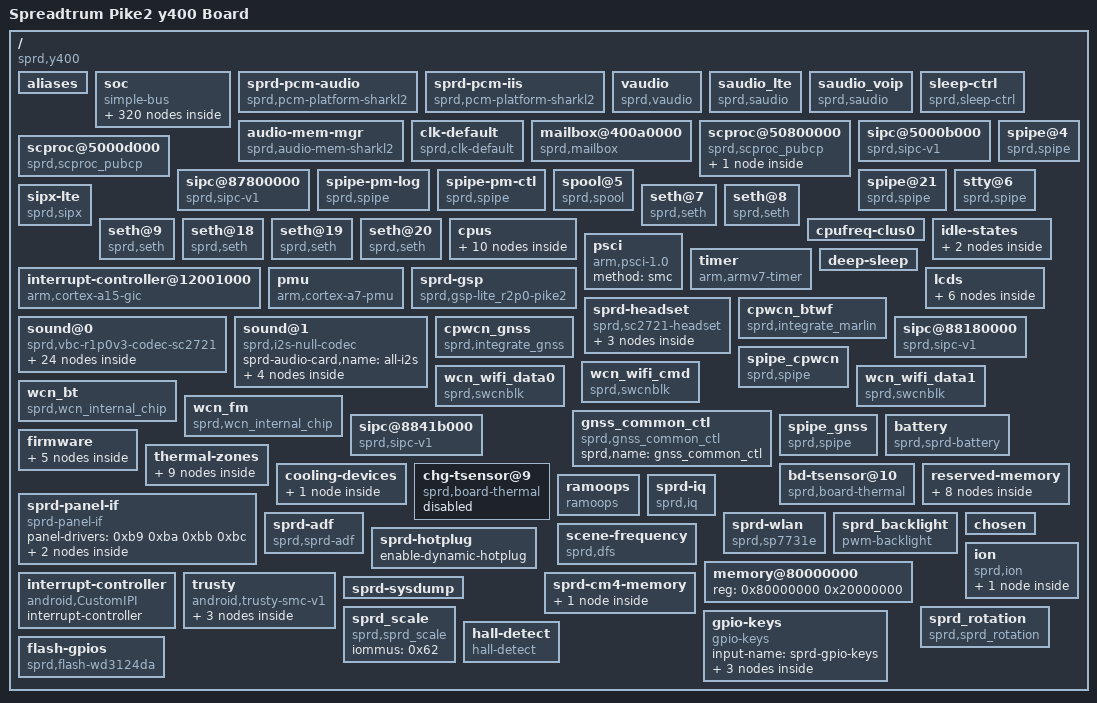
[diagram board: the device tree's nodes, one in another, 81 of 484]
/dts-v1/;

/ {
	interrupt-parent = <0x1>;
	#address-cells = <0x1>;
	#size-cells = <0x1>;
	cpuinfo_hardware = "Spreadtrum SC7731e";
	model = "Spreadtrum Pike2 y400 Board";
	compatible = "sprd,y400", "sprd,sc7731e";
	sprd,sc-id = <0x1e33 0x1 0x20000>;

	aliases {
		serial0 = "/soc/ap-apb/serial@70000000";
		serial1 = "/soc/ap-apb/serial@70100000";
		i2c0 = "/soc/ap-apb/i2c@70500000";
		i2c1 = "/soc/ap-apb/i2c@70600000";
		i2c2 = "/soc/ap-apb/i2c@70700000";
		spi0 = "/soc/ap-apb/spi@70a00000";
		spi1 = "/soc/ap-apb/spi@70b00000";
		hwspinlock1 = "/soc/aon/hwspinlock@40060000";
		thm-sensor0 = "/soc/aon/cpu-thm@402f0000";
		cooling-device0 = "/cooling-devices/cluster0-cooling";
		thm-sensor9 = "/chg-tsensor@9";
		thm-sensor10 = "/bd-tsensor@10";
		thm-sensor11 = "/thermal-zones/cpu-thmzone";
	};

	soc {
		compatible = "simple-bus";
		#address-cells = <0x1>;
		#size-cells = <0x1>;
		ranges;

		syscon@20e00000 {
			compatible = "sprd,sys-ap-ahb", "syscon";
			reg = <0x20e00000 0x100000>;
			hwlocks = <0x2 0x1>;
			hwlock-names = "syscon";
			linux,phandle = <0x2e>;
			phandle = <0x2e>;
		};

		syscon@33100000 {
			compatible = "sprd,anlg_wrap_wcn", "syscon";
			reg = <0x33100000 0x10000>;
			hwlocks = <0x2 0x1>;
			hwlock-names = "syscon";
			linux,phandle = <0xad>;
			phandle = <0xad>;
		};

		syscon@402b0000 {
			compatible = "sprd,sys-pmu-apb", "syscon";
			reg = <0x402b0000 0x10000>;
			hwlocks = <0x2 0x1>;
			hwlock-names = "syscon";
			linux,phandle = <0x4d>;
			phandle = <0x4d>;
		};

		syscon@402e0000 {
			compatible = "sprd,sys-aon-apb", "syscon";
			reg = <0x402e0000 0x10000>;
			hwlocks = <0x2 0x1>;
			hwlock-names = "syscon";
			linux,phandle = <0x16>;
			phandle = <0x16>;
		};

		syscon@40350000 {
			compatible = "sprd,anlg_phy_g1", "syscon";
			reg = <0x40350000 0x3000>;
			hwlocks = <0x2 0x1>;
			hwlock-names = "syscon";
		};

		syscon@40353000 {
			compatible = "sprd,anlg_phy_g2", "syscon";
			reg = <0x40353000 0x3000>;
			hwlocks = <0x2 0x1>;
			hwlock-names = "syscon";
		};

		syscon@40356000 {
			compatible = "sprd,anlg_phy_g3", "syscon";
			reg = <0x40356000 0x3000>;
			hwlocks = <0x2 0x1>;
			hwlock-names = "syscon";
		};

		syscon@40359000 {
			compatible = "sprd,anlg_phy_g5", "syscon";
			reg = <0x40359000 0x3000>;
			hwlocks = <0x2 0x1>;
			hwlock-names = "syscon";
		};

		syscon@60100000 {
			compatible = "sprd,sys-gpu-ahb", "syscon";
			reg = <0x60100000 0x100000>;
			hwlocks = <0x2 0x1>;
			hwlock-names = "syscon";
			linux,phandle = <0x5b>;
			phandle = <0x5b>;
		};

		syscon@60d00000 {
			compatible = "sprd,sys-mm-ahb", "syscon";
			reg = <0x60d00000 0x100000>;
			hwlocks = <0x2 0x1>;
			hwlock-names = "syscon";
			linux,phandle = <0x60>;
			phandle = <0x60>;
		};

		syscon@71300000 {
			compatible = "sprd,sys-ap-apb", "syscon";
			reg = <0x71300000 0x100000>;
			hwlocks = <0x2 0x1>;
			hwlock-names = "syscon";
			linux,phandle = <0x2d>;
			phandle = <0x2d>;
		};

		funnel-soc@10001000 {
			compatible = "arm,coresight-funnel", "arm,primecell";
			reg = <0x10001000 0x1000>;
			clocks = <0x3>;
			clock-names = "apb_pclk";

			ports {
				#address-cells = <0x1>;
				#size-cells = <0x0>;

				port@0 {
					reg = <0x0>;

					endpoint {
						remote-endpoint = <0x4>;
						linux,phandle = <0x6>;
						phandle = <0x6>;
					};
				};

				port@1 {
					reg = <0x0>;

					endpoint {
						slave-mode;
						remote-endpoint = <0x5>;
						linux,phandle = <0x7>;
						phandle = <0x7>;
					};
				};
			};
		};

		tmc-etb@10003000 {
			compatible = "arm,coresight-tmc", "arm,primecell";
			reg = <0x10003000 0x1000>;
			clocks = <0x3>;
			clock-names = "apb_pclk";

			port {

				endpoint {
					slave-mode;
					remote-endpoint = <0x6>;
					linux,phandle = <0x4>;
					phandle = <0x4>;
				};
			};
		};

		cs-ts@10009000 {
			compatible = "arm,coresight-ts", "arm,primecell";
			reg = <0x10009000 0x1000>;
		};

		funnel-core@10220000 {
			compatible = "arm,coresight-funnel", "arm,primecell";
			reg = <0x10220000 0x1000>;
			clocks = <0x3>;
			clock-names = "apb_pclk";

			ports {
				#address-cells = <0x1>;
				#size-cells = <0x0>;

				port@0 {
					reg = <0x0>;

					endpoint {
						remote-endpoint = <0x7>;
						linux,phandle = <0x5>;
						phandle = <0x5>;
					};
				};

				port@1 {
					reg = <0x0>;

					endpoint {
						slave-mode;
						remote-endpoint = <0x8>;
						linux,phandle = <0xf>;
						phandle = <0xf>;
					};
				};

				port@2 {
					reg = <0x1>;

					endpoint {
						slave-mode;
						remote-endpoint = <0x9>;
						linux,phandle = <0x11>;
						phandle = <0x11>;
					};
				};

				port@3 {
					reg = <0x2>;

					endpoint {
						slave-mode;
						remote-endpoint = <0xa>;
						linux,phandle = <0x13>;
						phandle = <0x13>;
					};
				};

				port@4 {
					reg = <0x3>;

					endpoint {
						slave-mode;
						remote-endpoint = <0xb>;
						linux,phandle = <0x15>;
						phandle = <0x15>;
					};
				};
			};
		};

		etm-core0@1025c000 {
			compatible = "arm,coresight-etm3x", "arm,primecell";
			reg = <0x1025c000 0x1000>;
			cpu = <0xc>;
			clocks = <0x3 0xd 0xe>;
			clock-names = "apb_pclk", "clk_cs", "cs_src";

			port {

				endpoint {
					remote-endpoint = <0xf>;
					linux,phandle = <0x8>;
					phandle = <0x8>;
				};
			};
		};

		etm-core1@1025d000 {
			compatible = "arm,coresight-etm3x", "arm,primecell";
			reg = <0x1025d000 0x1000>;
			cpu = <0x10>;
			clocks = <0x3 0xd 0xe>;
			clock-names = "apb_pclk", "clk_cs", "cs_src";

			port {

				endpoint {
					remote-endpoint = <0x11>;
					linux,phandle = <0x9>;
					phandle = <0x9>;
				};
			};
		};

		etm-core2@1025e000 {
			compatible = "arm,coresight-etm3x", "arm,primecell";
			reg = <0x1025e000 0x1000>;
			cpu = <0x12>;
			clocks = <0x3 0xd 0xe>;
			clock-names = "apb_pclk", "clk_cs", "cs_src";

			port {

				endpoint {
					remote-endpoint = <0x13>;
					linux,phandle = <0xa>;
					phandle = <0xa>;
				};
			};
		};

		etm-core3@1025f000 {
			compatible = "arm,coresight-etm3x", "arm,primecell";
			reg = <0x1025f000 0x1000>;
			cpu = <0x14>;
			clocks = <0x3 0xd 0xe>;
			clock-names = "apb_pclk", "clk_cs", "cs_src";

			port {

				endpoint {
					remote-endpoint = <0x15>;
					linux,phandle = <0xb>;
					phandle = <0xb>;
				};
			};
		};

		pub {
			compatible = "simple-bus";
			#address-cells = <0x1>;
			#size-cells = <0x1>;
			ranges;

			syscon@30000000 {
				compatible = "sprd,sys-dmc-phy", "syscon";
				reg = <0x30000000 0x400>;
				sprd,sizel_off = <0x1b4>;
				sprd,sizeh_off = <0x1b8>;
			};

			bm-perf@30040000 {
				compatible = "sprd,bm-perf-pike2";
				reg = <0x30040000 0x80000 0x0 0x0 0x40270000 0x10000 0x300e0000 0x4 0x0 0x0>;
				interrupts = <0x0 0x56 0x4>;
				reg-names = "pub0", "pub1", "timer", "pub0_glb", "pub1_glb";
				sprd,syscon-aon-glb = <0x16>;
				sprd,bm-dma = <0xb>;
				dma-names = "bm_chn";
				dmas = <0x17 0x9>;
			};

			dmc-mpu@300e0000 {
				compatible = "sprd,dmc-mpu-r3p0";
				reg = <0x300e0000 0x10000>;
				interrupts = <0x0 0x3d 0x4>;
				sprd,channel-num = <0x8>;
				sprd,channel-names = "WCN/AON", "GPU", "DISP/ISP", "CA7", "CP", "VSP", "AP", "SHARED";
				sprd,ranges = <0x88000000 0x88380000 0x0 0x0 0x0 0x0 0x0 0x0 0x0 0x0 0x0 0x0 0x0 0x0 0x0 0x0>;
				sprd,chn-config = <0x1 0x0 0x1 0x0 0x1 0x1 0x0 0x1 0x1 0x0 0x1 0x1 0x0 0x1 0x1 0x0 0x1 0x1 0x0 0x1 0x1 0x0 0x1 0x1>;
				sprd,id-config = <0x1 0xc0 0xc0 0x0 0x0 0x0 0x0 0x0 0x0 0x0 0x0 0x0 0x0 0x0 0x0 0x0 0x0 0x0 0x0 0x0 0x0 0x0 0x0 0x0>;
				sprd,shared-chn = "WCN/AON";
				sprd,ddr-offset = <0x80000000>;
				status = "okay";
				sprd,panic;
			};
		};

		ap-apb {
			compatible = "simple-bus";
			#address-cells = <0x1>;
			#size-cells = <0x1>;
			ranges;

			serial@70000000 {
				compatible = "sprd,sc9836-uart";
				reg = <0x70000000 0x100>;
				interrupts = <0x0 0x2 0x4>;
				clock-names = "uart", "source", "enable";
				status = "okay";
				clocks = <0x18 0x3 0x19 0xd>;
			};

			serial@70100000 {
				compatible = "sprd,sc9836-uart";
				reg = <0x70100000 0x100>;
				interrupts = <0x0 0x3 0x4>;
				clock-names = "uart", "source", "enable";
				status = "okay";
				clocks = <0x1a 0x3 0x19 0xe>;
			};

			i2c@70500000 {
				compatible = "sprd,r8p0-i2c";
				reg = <0x70500000 0x1000>;
				interrupts = <0x0 0xb 0x4>;
				clock-names = "i2c", "source", "enable";
				clock-frequency = <0x61a80>;
				#address-cells = <0x1>;
				#size-cells = <0x0>;
				status = "okay";
				clocks = <0x1b 0x3 0x19 0x8>;

				sensor-main@3c {
					compatible = "sprd,sensor-main";
					reg = <0x3c>;
					clock-names = "clk_src", "sensor_eb", "clk_96m", "clk_76m8", "clk_48m", "clk_26m";
					clocks = <0x1c 0x1d 0x1 0x1e 0x1f 0x20 0x3>;
					vddio-supply = <0x21>;
					vddcama-supply = <0x22>;
					vddcamd-supply = <0x23>;
					vddcammot-supply = <0x24>;
					reset-gpios = <0x25 0x25 0x0>;
					power-down-gpios = <0x25 0x26 0x0>;
					host = "dcam0";
					linux,phandle = <0x58>;
					phandle = <0x58>;

					port {

						endpoint {
							remote-endpoint = <0x26>;
						};
					};
				};

				sensor-sub@21 {
					compatible = "sprd,sensor-sub";
					reg = <0x21>;
					clock-names = "clk_src", "sensor_eb", "clk_96m", "clk_76m8", "clk_48m", "clk_26m";
					clocks = <0x1c 0x1d 0x1 0x1e 0x1f 0x20 0x3>;
					vddio-supply = <0x21>;
					vddcama-supply = <0x22>;
					vddcamd-supply = <0x23>;
					vddcammot-supply = <0x24>;
					reset-gpios = <0x25 0x2e 0x0>;
					power-down-gpios = <0x25 0x27 0x0>;
					host = "dcam0";
					linux,phandle = <0x59>;
					phandle = <0x59>;

					port {

						endpoint {
							remote-endpoint = <0x26>;
						};
					};
				};
			};

			i2c@70600000 {
				compatible = "sprd,r8p0-i2c";
				reg = <0x70600000 0x1000>;
				interrupts = <0x0 0xc 0x4>;
				clock-names = "i2c", "source", "enable";
				clock-frequency = <0x61a80>;
				#address-cells = <0x1>;
				#size-cells = <0x0>;
				status = "okay";
				clocks = <0x27 0x3 0x19 0x9>;

				accelerometer@26 {
					compatible = "da,da213";
					reg = <0x26>;
				};

				megnetometer@0c {
					compatible = "vtc,af6133";
					reg = <0xc>;
				};

				elan@49 {
					reg = <0x49>;
					compatible = "epl,epl259x";
					epl,irq-gpio = <0x25 0x38 0x0>;
				};

				kionix_acc@0e {
					compatible = "Kionix,accel";
					reg = <0xe>;
					poll_interval = <0xa>;
					min_interval = <0xa>;
					g_range = <0x0>;
					accel_res = <0x3>;
					accel_irq_use_drdy = <0x0>;
					accel_direction = <0x2>;
					gpios = <0x25 0x36 0x0>;
				};
			};

			i2c@70700000 {
				compatible = "sprd,r8p0-i2c";
				reg = <0x70700000 0x1000>;
				interrupts = <0x0 0xd 0x4>;
				clock-names = "i2c", "source", "enable";
				clock-frequency = <0x30d40>;
				#address-cells = <0x1>;
				#size-cells = <0x0>;
				status = "okay";
				clocks = <0x28 0x3 0x19 0xa>;

				ilitek2238_ts@26 {
					status = "okay";
					compatible = "ilitek,2238";
					reg = <0x26>;
					gpios = <0x25 0x3f 0x0 0x25 0x40 0x0>;
					touch,reset-gpio = <0x25 0x3f 0x0>;
					touch,irq-gpio = <0x25 0x40 0x0>;
					vdd_name = "vdd18";
					virtualkeys = <0x190 0x384 0x1e 0x1e 0x50 0x384 0x1e 0x1e 0xf0 0x384 0x1e 0x1e>;
					TP_MAX_X = <0x1e0>;
					TP_MAX_Y = <0x3c0>;
				};

				focaltech@38 {
					compatible = "focaltech,fts";
					reg = <0x38>;
					focaltech,reset-gpio = <0x25 0x3f 0x0>;
					focaltech,irq-gpio = <0x25 0x40 0x0>;
					focaltech,max-touch-number = <0x2>;
					focaltech,display-coords = <0x0 0x0 0x1e0 0x3c0>;
					#focaltech,have-key;
					#focaltech,key-number = <0x3>;
					#focaltech,keys = <0x9e 0xac 0x244>;
					#focaltech,key-y-coord = <0x384>;
					#focaltech,key-x-coords = <0x50 0xf0 0x190>;
				};

				bl_ts@2d {
					compatible = "btl,btl_ts";
					reg = <0x2d>;
					btl,reset-gpio = <0x25 0x3f 0x0>;
					btl,irq-gpio = <0x25 0x40 0x0>;
					vdd_name = "vdd28";
					betterlife,have_virtualkey;
					betterlife,virtualkeys = <0x50 0x384 0x3c 0x2d 0xf0 0x384 0x3c 0x2d 0x190 0x384 0x3c 0x2d>;
					TP_MAX_X = <0x1e0>;
					TP_MAX_Y = <0x3c0>;
				};
			};

			spi@70a00000 {
				compatible = "sprd,spi-r4p0";
				reg = <0x70a00000 0x1000>;
				interrupts = <0x0 0x7 0x4>;
				clock-names = "spi", "source", "enable";
				sprd,dma-mode = <0x0>;
				sprd,rxtx-dma = <0xb 0xc>;
				dma-names = "rx_chn", "tx_chn";
				dmas = <0x29 0xb 0x29 0xc>;
				#address-cells = <0x1>;
				#size-cells = <0x0>;
				status = "disabled";
				clocks = <0x2a 0x3 0x19 0x5>;
			};

			spi@70b00000 {
				compatible = "sprd,spi-r4p0";
				reg = <0x70b00000 0x1000>;
				interrupts = <0x0 0x8 0x4>;
				clock-names = "spi", "source", "enable";
				sprd,dma-mode = <0x0>;
				sprd,rxtx-dma = <0xd 0xe>;
				dma-names = "rx_chn", "tx_chn";
				dmas = <0x29 0xd 0x29 0xe>;
				#address-cells = <0x1>;
				#size-cells = <0x0>;
				status = "disabled";
				clocks = <0x2b 0x3 0x2c 0x9>;
			};

			i2s@70d00000 {
				compatible = "sprd,i2s";
				#sound-dai-cells = <0x0>;
				reg = <0x70d00000 0x100000>;
				sprd,dai_name = "i2s_bt_sco0";
				sprd,hw_port = <0x0>;
				sprd,syscon-ap-apb = <0x2d>;
				status = "okay";
				sprd,config_type = "pcm";
				sprd,slave_timeout = <0xf11>;
				sprd,_hw_port = <0x0>;
				sprd,fs = <0x1f40>;
				sprd,bus_type = <0x1>;
				sprd,rtx_mode = <0x3>;
				sprd,byte_per_chan = <0x1>;
				sprd,slave_mode = <0x0>;
				sprd,lsb = <0x0>;
				sprd,lrck = <0x0>;
				sprd,low_for_left = <0x1>;
				sprd,clk_inv = <0x0>;
				sprd,pcm_short_frame = <0x1>;
				sprd,pcm_slot = <0x1>;
				sprd,pcm_cycle = <0x1>;
				sprd,tx_watermark = <0xc>;
				sprd,rx_watermark = <0x14>;
				linux,phandle = <0xac>;
				phandle = <0xac>;
			};

			i2s@70e00000 {
				compatible = "sprd,i2s";
				#sound-dai-cells = <0x0>;
				reg = <0x70e00000 0x100000>;
				sprd,dai_name = "i2s_bt_sco1";
				sprd,hw_port = <0x1>;
				sprd,syscon-ap-apb = <0x2d>;
				status = "disable";
			};

			i2s@70f00000 {
				compatible = "sprd,i2s";
				#sound-dai-cells = <0x0>;
				reg = <0x70f00000 0x100000>;
				sprd,dai_name = "i2s_bt_sco2";
				sprd,hw_port = <0x2>;
				sprd,syscon-ap-apb = <0x2d>;
				status = "disable";
			};

			i2s@71000000 {
				compatible = "sprd,i2s";
				#sound-dai-cells = <0x0>;
				reg = <0x71000000 0x100000>;
				sprd,dai_name = "i2s_bt_sco3";
				sprd,hw_port = <0x3>;
				sprd,syscon-ap-apb = <0x2d>;
				status = "disable";
			};

			syscon@71400000 {
				compatible = "sprd,sys-ap-intc", "syscon";
				reg = <0x71400000 0x10000>;
				linux,phandle = <0x9a>;
				phandle = <0x9a>;
			};

			syscon@71500000 {
				compatible = "sprd,sys-ap-intc", "syscon";
				reg = <0x71500000 0x10000>;
				linux,phandle = <0x9b>;
				phandle = <0x9b>;
			};

			syscon@71600000 {
				compatible = "sprd,sys-ap-intc", "syscon";
				reg = <0x71600000 0x10000>;
				linux,phandle = <0x9c>;
				phandle = <0x9c>;
			};

			syscon@71700000 {
				compatible = "sprd,sys-ap-intc", "syscon";
				reg = <0x71700000 0x10000>;
				linux,phandle = <0x9d>;
				phandle = <0x9d>;
			};
		};

		ap-ahb {
			compatible = "simple-bus";
			#address-cells = <0x1>;
			#size-cells = <0x1>;
			ranges;

			dma-controller@20100000 {
				compatible = "sprd,ap-dma-v2.0";
				reg = <0x20100000 0x4000>;
				interrupts = <0x0 0x32 0x4>;
				#dma-cells = <0x1>;
				#dma-channels = <0x1c>;
				sprd,full-type-offset = <0x0>;
				sprd,syscon-dma-glb = <0x2e>;
				clock-names = "enable";
				clocks = <0x2f 0x5>;
				linux,phandle = <0x29>;
				phandle = <0x29>;
			};

			usb@20200000 {
				compatible = "sprd,usb";
				reg = <0x20200000 0x2000>;
				interrupts = <0x0 0x37 0x4>;
				interrupt-names = "mc";
				clocks = <0x2f 0x4>;
				clock-names = "core_clk";
				phy-type = "usb20_sprd_phy";
				usb-phy = <0x30>;
				phy-names = "usb";
				dr-mode = "peripheral";
				sprd,cable-detection-method = "gpios";
				sprd,vbus-gpios = <0x31 0x0 0x0>;
			};

			sdio@20600000 {
				compatible = "sprd,sdhc-r10";
				reg = <0x20600000 0x1000>;
				interrupts = <0x0 0x3c 0x4>;
				clock-names = "sdio_clk", "sdio_clk_source", "sdio_ahb_enable", "sdio_2x_eb", "sdio_1x_eb";
				clocks = <0x32 0x33 0x2f 0xb 0x2c 0x1 0x2c 0x0>;
				status = "okay";
				sprd,hs400es-dly = <0x45 0x7f 0x30 0x30>;
				sprd,hs400-dly = <0x45 0xaa 0x30 0x30>;
				sprd,hs200-dly = <0x7f 0xaa 0xa8 0xa8>;
				sprd,ddr52-dly = <0x80 0xbe 0x22 0x22>;
				vmmc-supply = <0x34>;
				voltage-ranges = <0xbb8 0xbb8>;
				bus-width = <0x8>;
				non-removable;
				cap-mmc-hw-reset;
				mmc-hs200-1_8v;
				mmc-ddr-1_8v;
				sprd,name = "sdio_emmc";
				no-sdio;
				no-sd;
			};

			sdio@20300000 {
				compatible = "sprd,sdhc-r10";
				reg = <0x20300000 0x1000>;
				interrupts = <0x0 0x39 0x4>;
				clock-names = "sdio_clk", "sdio_clk_source", "sdio_ahb_enable", "sdio_2x_eb", "sdio_1x_eb";
				clocks = <0x35 0x33 0x2f 0x8 0x2c 0x3 0x2c 0x2>;
				status = "okay";
				sprd,sdr104-dly = <0x7f 0xb0 0xb4 0xb4>;
				sprd,sdr50-dly = <0x7f 0x45 0x41 0x41>;
				vmmc-supply = <0x36>;
				vqmmc-supply = <0x37>;
				voltage-ranges = <0xbb8 0xbb8>;
				bus-width = <0x4>;
				sd-uhs-sdr50;
				sprd,name = "sdio_sd";
				no-sdio;
				no-mmc;
			};

			iommu@20800160 {
				compatible = "sprd,iommuexpk2-dispc";
				reg = <0x20800160 0x4 0x20800800 0x60 0x30000000 0x8000000>;
				reg_name = "mmu_interrupt_reg", "mmu_reg", "iova pool";
				status = "okay";
				#iommu-cells = <0x0>;
				linux,phandle = <0x3e>;
				phandle = <0x3e>;
			};

			gsp@20a00000 {
				compatible = "sprd,gsp-core";
				reg = <0x20a00000 0x1000 0x20443000 0x138>;
				core-id = <0x0>;
				kcfg-num = <0x8>;
				interrupts = <0x0 0x33 0x4>;
				iommus = <0x38>;
				sprd,sys-ap-ahb = <0x2e>;
				clock-names = "clk_gsp", "clk_gsp_parent", "clk_gsp_eb";
				clocks = <0x39 0x33 0x2f 0x3>;
				linux,phandle = <0x9e>;
				phandle = <0x9e>;
			};

			iommu@20a00800 {
				compatible = "sprd,iommuexpk2-gsp";
				reg = <0x20a00800 0x4 0x20a00804 0x60 0x10000000 0x10000000>;
				reg_name = "mmu_interrupt_reg", "mmu_reg", "iova pool";
				status = "okay";
				#iommu-cells = <0x0>;
				linux,phandle = <0x38>;
				phandle = <0x38>;
			};

			hsphy@20e00000 {
				compatible = "sprd,pike2-usb-phy";
				reg = <0x20e00000 0x3030>;
				reg-names = "phy_glb_regs";
				sprd,syscon-enable = <0x16>;
				sprd,tune-value = <0x5af33>;
				sprd,vdd-voltage = <0x325aa0>;
				#phy-cells = <0x0>;
				vdd-supply = <0x3a>;
				sprd,efuse-blk-id = <0x29>;
				sprd,efuse-backup = <0x1>;
				linux,phandle = <0x30>;
				phandle = <0x30>;
			};

			dispc@20800000 {
				compatible = "sprd,display-controller";
				reg = <0x20800000 0x1000>;
				dev-id = <0x0>;
				sprd,dpi_clk_div = <0x1>;
				sprd,max_layers = <0x4>;
				sprd,qos = <0x411f0>;
				interrupts = <0x0 0x2e 0x4>;
				clock-src = <0x16e36000 0x927c000>;
				clock-names = "clk_dispc_core_parent", "clk_dispc_dpi_parent", "clk_dispc_core", "clk_dispc_dpi", "clk_dispc_ahb_eb";
				clocks = <0x33 0x3b 0x3c 0x3d 0x2f 0x1>;
				iommus = <0x3e>;
				status = "okay";
				sprd,ip = "dpu-lite-r1p0";
				sprd,soc = "pike2";
				wb-disable = <0x1>;
				linux,phandle = <0xbe>;
				phandle = <0xbe>;

				port {

					endpoint@0 {
						remote-endpoint = <0x3f>;
						linux,phandle = <0x41>;
						phandle = <0x41>;
					};
				};
			};

			dsi@21800000 {
				compatible = "sprd,dsi-controller";
				#address-cells = <0x1>;
				#size-cells = <0x0>;
				dev-id = <0x0>;
				reg = <0x21800000 0x1000>;
				interrupts = <0x0 0x30 0x4 0x0 0x31 0x4>;
				clock-names = "clk_dsi0_ahb_eb";
				clocks = <0x2f 0x0>;
				status = "okay";
				sprd,ip = "sprd,dsi-ctrl-r1p0";
				sprd,soc = "pike2";

				port@0 {
					reg = <0x0>;

					endpoint {
						remote-endpoint = <0x40>;
						linux,phandle = <0x43>;
						phandle = <0x43>;
					};
				};

				port@1 {
					reg = <0x1>;

					endpoint {
						remote-endpoint = <0x41>;
						linux,phandle = <0x3f>;
						phandle = <0x3f>;
					};
				};
			};

			dphy@0 {
				compatible = "sprd,mipi-dsi-phy";
				#address-cells = <0x1>;
				#size-cells = <0x0>;
				reg = <0x21800000 0x1000>;
				status = "okay";
				sprd,ip = "sprd,megacores-sharkle";
				sprd,soc = "pike2";

				port@0 {
					reg = <0x0>;

					endpoint {
						remote-endpoint = <0x42>;
						linux,phandle = <0xbd>;
						phandle = <0xbd>;
					};
				};

				port@1 {
					reg = <0x1>;

					endpoint {
						remote-endpoint = <0x43>;
						linux,phandle = <0x40>;
						phandle = <0x40>;
					};
				};
			};

			lcds {

				lcdffff@0 {
					work-mode = <0x1>;
					bpp = <0x18>;
					lane-number = <0x4>;
					fps = <0x3c>;
					panel-name = "lcd_dummy_mipi_hd";
					power-on-sequence = <0x32 0x1 0x14 0x32 0x0 0x14 0x32 0x1 0x78>;
					power-off-sequence = <0x32 0x0 0x14>;
					init-data = <0x15780002 0x11001500 0x22900>;
					sleep-in = <0x15000002 0x28001578 0x21000>;
					sleep-out = <0x15780002 0x11001500 0x22900>;
					linux,phandle = <0xbc>;
					phandle = <0xbc>;

					display-timings {
						clock-frequency = <0x7a120>;
						hactive = <0x2d0>;
						vactive = <0x500>;
						hback-porch = <0x30>;
						hfront-porch = <0x30>;
						vback-porch = <0x10>;
						vfront-porch = <0x10>;
						hsync-len = <0x8>;
						vsync-len = <0x8>;
					};
				};
			};
		};

		aon {
			compatible = "simple-bus";
			#address-cells = <0x1>;
			#size-cells = <0x1>;
			ranges;

			syscon@0 {
				compatible = "sprd,sys-aon-iram0", "syscon";
				reg = <0x0 0x2000>;
			};

			timer@40050000 {
				compatible = "sprd,bcevt-r4p0";
				reg = <0x40050000 0x14>;
				interrupts = <0x0 0x1c 0x4>;
				clock-frequency = <0x8000>;
			};

			timer@40050020 {
				compatible = "sprd,persistent-clock";
				reg = <0x40050020 0x14>;
				clock-frequency = <0x8000>;
			};

			timer@40050040 {
				compatible = "sprd,gp-timer";
				reg = <0x40050040 0x14>;
				clock-frequency = <0x18cba80>;
				status = "disabled";
			};

			hwspinlock@40060000 {
				compatible = "sprd,hwspinlock-r3p0";
				reg = <0x40060000 0x1000>;
				#hwlock-cells = <0x1>;
				hwlocks-base = <0x0>;
				hwlocks-num = <0x20>;
				clock-names = "enable";
				clocks = <0x44 0x16>;
				linux,phandle = <0x2>;
				phandle = <0x2>;
			};

			dma-controller@40100000 {
				compatible = "sprd,aon-dma-v2.0";
				reg = <0x40100000 0x4000>;
				#dma-cells = <0x1>;
				#dma-channels = <0xd>;
				sprd,full-type-offset = <0x0>;
				sprd,syscon-dma-glb = <0x16>;
				clock-names = "enable";
				clocks = <0x45 0x16>;
				linux,phandle = <0x17>;
				phandle = <0x17>;
			};

			syscon@40200000 {
				compatible = "sprd,sys-aon-intc", "syscon";
				reg = <0x40200000 0x10000>;
				linux,phandle = <0x9f>;
				phandle = <0x9f>;
			};

			gpio-controller@40210000 {
				compatible = "sprd,ap-eic";
				reg = <0x40210000 0x1000 0x40370000 0x1000>;
				gpio-controller;
				#gpio-cells = <0x2>;
				sprd,gpiobase = <0x120>;
				sprd,ngpios = <0x20>;
				interrupt-controller;
				#interrupt-cells = <0x2>;
				interrupts = <0x0 0x25 0x4>;
				linux,phandle = <0xc5>;
				phandle = <0xc5>;
			};

			gpio-controller@402100a0 {
				compatible = "sprd,ap-eic-async";
				reg = <0x402100a0 0x40 0x403700a0 0x40>;
				gpio-controller;
				#gpio-cells = <0x2>;
				sprd,gpiobase = <0x150>;
				sprd,ngpios = <0x20>;
				interrupt-controller;
				#interrupt-cells = <0x2>;
				interrupts = <0x0 0x25 0x4>;
			};

			efuse@40240000 {
				compatible = "sprd,ap_r6p0_efuse";
				sprd,syscon-enable = <0x16>;
				reg = <0x40240000 0x10000>;
				clock-names = "enable";
				clocks = <0x44 0xd>;
				sprd,uid-start = <0x2e 0x1>;
				sprd,uid-end = <0x2f 0x1>;
				sprd,block-start = <0x24>;
				sprd,block-num = <0xc>;
				sprd,block-width = <0x20>;
				hwlocks = <0x2 0x8>;
				hwlock-names = "ap_efuse";
			};

			pwm@40260020 {
				#pwm-cells = <0x2>;
				compatible = "sprd,pwm-r3p0";
				reg = <0x40260020 0x10000>;
				status = "okay";
				clock-names = "sprd_pwm_clk_parent", "clk_pwm";
				clocks = <0x3 0x46>;
				linux,phandle = <0xbf>;
				phandle = <0xbf>;
			};

			gpio-controller@40280000 {
				compatible = "sprd,ap-gpio";
				reg = <0x40280000 0x1000>;
				gpio-controller;
				#gpio-cells = <0x2>;
				sprd,gpiobase = <0x0>;
				sprd,ngpios = <0x100>;
				interrupt-controller;
				#interrupt-cells = <0x2>;
				interrupts = <0x0 0x23 0x4>;
				linux,phandle = <0x25>;
				phandle = <0x25>;
			};

			pinctrl@402a0000 {
				compatible = "sprd,sc9833-pinctrl";
				reg = <0x402a0000 0x10000>;

				reg3-iis0-0 {
					pins = <0x2810643 0x0>;
					linux,phandle = <0x4f>;
					phandle = <0x4f>;
				};

				reg3-iis0-1 {
					pins = <0x2810643 0x1>;
					linux,phandle = <0x51>;
					phandle = <0x51>;
				};

				reg3-iis0-2 {
					pins = <0x2810643 0x2>;
					linux,phandle = <0x50>;
					phandle = <0x50>;
				};

				reg3-iis0-3 {
					pins = <0x2810643 0x3>;
					linux,phandle = <0x52>;
					phandle = <0x52>;
				};

				reg3-iis1-0 {
					pins = <0x2710a33 0x0>;
					linux,phandle = <0x53>;
					phandle = <0x53>;
				};

				reg3-iis1-1 {
					pins = <0x2710a33 0x1>;
					linux,phandle = <0x55>;
					phandle = <0x55>;
				};

				reg3-iis1-2 {
					pins = <0x2710a33 0x2>;
					linux,phandle = <0x54>;
					phandle = <0x54>;
				};

				reg3-iis1-3 {
					pins = <0x2710a33 0x3>;
					linux,phandle = <0x56>;
					phandle = <0x56>;
				};
			};

			avoid-disturb@402e01b0 {
				compatible = "sprd,pike2-ads";
				reg = <0x402e01b0 0x14 0x5000f800 0x800>;
				sprd,ads-off-info = <0x10 0x20 0x20 0x80 0x220 0x800>;
				sprd,sad-dst-id = <0x2 0x3 0x4>;
				sprd,pll-index = <0x1 0x3 0x4>;
				clocks = <0x47 0x48 0x49>;
			};

			cpu-thm@402f0000 {
				compatible = "sprd,r2p0-thm";
				sprd,syscon-enable = <0x16>;
				reg = <0x402f0000 0x10000>;
				clock-names = "enable";
				clocks = <0x45 0x1>;
				#thermal-sensor-cells = <0x1>;
				power-down = <0x0>;
				otp-temp = <0x1d4c0>;
				algor_ver = <0x1>;
				cal_k = <0x387>;
				cal_b = <0x1167a>;
				cal_efuse_blk = <0x2c>;
				cal_efuse_bit = <0xc>;
				ratio_off_bit = <0x5>;
				ratio_sign_bit = <0x4>;
				linux,phandle = <0xb2>;
				phandle = <0xb2>;
			};

			watchdog@40310000 {
				compatible = "sprd,sharkl2-wdt";
				reg = <0x40310000 0x1000>;
				interrupts = <0x0 0x7c 0x4>;
				clock-names = "enable", "rtc_enable";
				sprd,wdt-enable = <0x16>;
				sprd,wdt-phandle = <0x4a>;
				clocks = <0x45 0x8 0x4b 0x9>;
			};

			spi@403c0000 {
				compatible = "sprd,r3p0-adi";
				reg = <0x403c0000 0x10000>;
				#address-cells = <0x1>;
				#size-cells = <0x0>;
				sprd,hw-channels = <0x3 0x8c68 0x21 0x8c20 0x23 0x8cc0 0x24 0x8ccc>;

				pmic@0 {
					compatible = "sprd,sc2720";
					reg = <0x0>;
					spi-max-frequency = <0x18cba80>;
					#address-cells = <0x1>;
					#size-cells = <0x0>;
					interrupt-controller;
					#interrupt-cells = <0x2>;
					interrupts = <0x0 0x26 0x4>;
					sprd,pmic_intc_base = <0xc0>;
					sprd,pmic_intc_irqmax = <0x9>;
					linux,phandle = <0x4c>;
					phandle = <0x4c>;

					timer@00 {
						compatible = "sprd,sc2720-chg-timer";
						reg = <0x0>;
						interrupt-parent = <0x4c>;
						interrupts = <0x6 0x4>;
					};

					watchdog@40 {
						compatible = "sprd,sc2720-wdt";
						reg = <0x40>;
						linux,phandle = <0x4a>;
						phandle = <0x4a>;
					};

					bltc-rgb@180 {
						compatible = "sprd,sc2720-bltc-rgb";
						reg = <0x180>;
						status = "okay";
					};

					flash@1f4 {
						compatible = "sprd,sc2720-flash";
						reg = <0x1f4>;
						status = "okay";
					};

					rtc@200 {
						compatible = "sprd,sc2720-rtc";
						interrupt-parent = <0x4c>;
						interrupts = <0x1 0x4>;
						reg = <0x200>;
					};

					gpio-controller@280 {
						compatible = "sprd,sc2720-eic";
						reg = <0x280>;
						interrupts = <0x4 0x4>;
						interrupt-parent = <0x4c>;
						gpio-controller;
						#gpio-cells = <0x2>;
						sprd,gpiobase = <0x140>;
						sprd,ngpios = <0x10>;
						interrupt-controller;
						#interrupt-cells = <0x2>;
						linux,phandle = <0x31>;
						phandle = <0x31>;
					};

					kpled@1f8 {
						compatible = "sprd,sc2721-kpled";
						brightness_max = <0xff>;
						brightness_min = <0x0>;
						run_mode = <0x1>;
						reg = <0x1f8 0x1fc>;
						status = "disabled";
					};

					efuse@300 {
						compatible = "sprd,sc2720-efuse";
						reg = <0x300>;
						sprd,block-num = <0x20>;
						sprd,block-width = <0x10>;
						hwlocks = <0x2 0xc>;
						hwlock-names = "pmic_efuse";
					};

					typec@380 {
						compatible = "sprd,typec";
						interrupt-parent = <0x4c>;
						interrupts = <0x8 0x4>;
						reg = <0x380>;
						mode = <0x2>;
						tsleep = <0x0>;
						ext-ldo-sw = <0x0>;
						status = "disable";
					};

					adc@400 {
						compatible = "sprd,sc2720-adc";
						reg = <0x400>;
						#io-channel-cells = <0x1>;
						sprd,channel-scale = <0x0 0x0 0x1 0x0 0x2 0x0 0x3 0x0>;
						hwlocks = <0x2 0x4>;
						hwlock-names = "pmic_adc";
						linux,phandle = <0xa5>;
						phandle = <0xa5>;
					};

					audio-codec@700 {
						compatible = "sprd,sc2720-audio-codec";
						#sound-dai-cells = <0x1>;
						reg = <0x700>;
						interrupts = <0x5 0x0>;
						interrupt-parent = <0x4c>;
						sprd,syscon-pmu-apb = <0x4d>;
						status = "okay";
						digital-codec = <0x4e>;
						linux,phandle = <0xa9>;
						phandle = <0xa9>;
					};

					fgu@a00 {
						compatible = "sprd,sc2720-fgu";
						reg = <0xa00>;
						interrupt-parent = <0x4c>;
						interrupts = <0x3 0x4>;
						ocv-type = <0x1>;
					};

					global@c00 {
						compatible = "sprd,pmic-glb";
						reg = <0xc00>;
					};

					power-controller@c00 {
						compatible = "sprd,sc2720-regulator";
						reg = <0xc28 0xcd4 0xd00 0xd1c 0xd20 0xd3c>;

						regulators {
							#address-cells = <0x1>;
							#size-cells = <0x0>;

							dcdc@0 {
								reg = <0x0>;
								regulator-name = "vddcore";
								sprd,default-microvolt = <0xdbba0>;
								sprd,step-microvolt = <0xc35>;
								regulator-min-microvolt = <0x1>;
								regulator-max-microvolt = <0x16e360>;
								regulator-microvolt-offset = <0x0>;
								sprd,hide-offset = <0x3e8>;
								sprd,default-on;
								sprd,hw-regulator;
								sprd,hw-step = <0x186a>;
								linux,phandle = <0x5a>;
								phandle = <0x5a>;
							};

							dcdc@1 {
								reg = <0x1>;
								regulator-name = "vddgen";
								sprd,default-microvolt = <0x1c3a90>;
								sprd,step-microvolt = <0x30d4>;
								regulator-min-microvolt = <0x13d620>;
								regulator-max-microvolt = <0x2ab980>;
								regulator-microvolt-offset = <0x0>;
								sprd,hide-offset = <0x3e8>;
								sprd,default-on;
							};

							dcdc@2 {
								reg = <0x2>;
								regulator-name = "vddwpa";
								sprd,default-microvolt = <0x2dc6c0>;
								sprd,step-microvolt = <0x61a8>;
								regulator-min-microvolt = <0x61a80>;
								regulator-max-microvolt = <0x36dee0>;
								regulator-microvolt-offset = <0x0>;
								sprd,hide-offset = <0x3e8>;
							};

							ldo@3 {
								reg = <0x3>;
								regulator-name = "avdd18";
								sprd,default-microvolt = <0x1b7740>;
								sprd,step-microvolt = <0x30d4>;
								regulator-min-microvolt = <0x155cc0>;
								regulator-max-microvolt = <0x2160ec>;
								regulator-microvolt-offset = <0x0>;
								sprd,hide-offset = <0x3e8>;
							};

							ldo@4 {
								reg = <0x4>;
								regulator-name = "vddcamio";
								sprd,default-microvolt = <0x1b7740>;
								sprd,step-microvolt = <0x30d4>;
								regulator-min-microvolt = <0x155cc0>;
								regulator-max-microvolt = <0x2160ec>;
								regulator-microvolt-offset = <0x0>;
								sprd,hide-offset = <0x3e8>;
								linux,phandle = <0x21>;
								phandle = <0x21>;
							};

							ldo@5 {
								reg = <0x5>;
								regulator-name = "vddrf18a";
								sprd,default-microvolt = <0x1b7740>;
								sprd,step-microvolt = <0x30d4>;
								regulator-min-microvolt = <0x155cc0>;
								regulator-max-microvolt = <0x2160ec>;
								regulator-microvolt-offset = <0x0>;
								sprd,hide-offset = <0x3e8>;
							};

							ldo@6 {
								reg = <0x6>;
								regulator-name = "vddrf18b";
								sprd,default-microvolt = <0x1b7740>;
								sprd,step-microvolt = <0x30d4>;
								regulator-min-microvolt = <0x155cc0>;
								regulator-max-microvolt = <0x2160ec>;
								regulator-microvolt-offset = <0x0>;
								sprd,hide-offset = <0x3e8>;
							};

							ldo@7 {
								reg = <0x7>;
								regulator-name = "vddcamd";
								sprd,default-microvolt = <0x124f80>;
								sprd,step-microvolt = <0x30d4>;
								regulator-min-microvolt = <0xc3500>;
								regulator-max-microvolt = <0x18392c>;
								regulator-microvolt-offset = <0x0>;
								sprd,hide-offset = <0x3e8>;
								linux,phandle = <0x23>;
								phandle = <0x23>;
							};

							ldo@8 {
								reg = <0x8>;
								regulator-name = "vddcon";
								sprd,default-microvolt = <0x124f80>;
								sprd,step-microvolt = <0x30d4>;
								regulator-min-microvolt = <0xc3500>;
								regulator-max-microvolt = <0x18392c>;
								regulator-microvolt-offset = <0x0>;
								sprd,hide-offset = <0x3e8>;
								linux,phandle = <0xaf>;
								phandle = <0xaf>;
							};

							ldo@9 {
								reg = <0x9>;
								regulator-name = "vddmem";
								sprd,default-microvolt = <0x124f80>;
								sprd,step-microvolt = <0x30d4>;
								regulator-min-microvolt = <0xc3500>;
								regulator-max-microvolt = <0x18392c>;
								regulator-microvolt-offset = <0x0>;
								sprd,hide-offset = <0x3e8>;
							};

							ldo@10 {
								reg = <0xa>;
								regulator-name = "vddsim0";
								sprd,default-microvolt = <0x2dc6c0>;
								sprd,step-microvolt = <0x30d4>;
								regulator-min-microvolt = <0x189ad4>;
								regulator-max-microvolt = <0x30d400>;
								regulator-microvolt-offset = <0x0>;
								sprd,hide-offset = <0x3e8>;
							};

							ldo@11 {
								reg = <0xb>;
								regulator-name = "vddsim1";
								sprd,default-microvolt = <0x2dc6c0>;
								sprd,step-microvolt = <0x30d4>;
								regulator-min-microvolt = <0x189ad4>;
								regulator-max-microvolt = <0x30d400>;
								regulator-microvolt-offset = <0x0>;
								sprd,hide-offset = <0x3e8>;
							};

							ldo@12 {
								reg = <0xc>;
								regulator-name = "vddsim2";
								sprd,default-microvolt = <0x2dc6c0>;
								sprd,step-microvolt = <0x30d4>;
								regulator-min-microvolt = <0x189ad4>;
								regulator-max-microvolt = <0x30d400>;
								regulator-microvolt-offset = <0x0>;
								sprd,hide-offset = <0x3e8>;
							};

							ldo@13 {
								reg = <0xd>;
								regulator-name = "vddcama";
								sprd,default-microvolt = <0x2ab980>;
								sprd,step-microvolt = <0x30d4>;
								regulator-min-microvolt = <0x189ad4>;
								regulator-max-microvolt = <0x30d400>;
								regulator-microvolt-offset = <0x0>;
								sprd,hide-offset = <0x3e8>;
								linux,phandle = <0x22>;
								phandle = <0x22>;
							};

							ldo@14 {
								reg = <0xe>;
								regulator-name = "vddcammot";
								sprd,default-microvolt = <0x2dc6c0>;
								sprd,step-microvolt = <0x30d4>;
								regulator-min-microvolt = <0x1e8480>;
								regulator-max-microvolt = <0x36bdac>;
								regulator-microvolt-offset = <0x0>;
								sprd,hide-offset = <0x3e8>;
								linux,phandle = <0x24>;
								phandle = <0x24>;
							};

							ldo@15 {
								reg = <0xf>;
								regulator-name = "vddemmccore";
								sprd,default-microvolt = <0x2dc6c0>;
								sprd,step-microvolt = <0x30d4>;
								regulator-min-microvolt = <0x1e8480>;
								regulator-max-microvolt = <0x36bdac>;
								regulator-microvolt-offset = <0x0>;
								sprd,hide-offset = <0x3e8>;
								linux,phandle = <0x34>;
								phandle = <0x34>;
							};

							ldo@16 {
								reg = <0x10>;
								regulator-name = "vddsdcore";
								sprd,default-microvolt = <0x2dc6c0>;
								sprd,step-microvolt = <0x30d4>;
								regulator-min-microvolt = <0x1e8480>;
								regulator-max-microvolt = <0x36bdac>;
								regulator-microvolt-offset = <0x0>;
								sprd,hide-offset = <0x3e8>;
								linux,phandle = <0x36>;
								phandle = <0x36>;
							};

							ldo@17 {
								reg = <0x11>;
								regulator-name = "vddsdio";
								sprd,default-microvolt = <0x2dc6c0>;
								sprd,step-microvolt = <0x30d4>;
								regulator-min-microvolt = <0x189ad4>;
								regulator-max-microvolt = <0x30d400>;
								regulator-microvolt-offset = <0x0>;
								sprd,hide-offset = <0x3e8>;
								linux,phandle = <0x37>;
								phandle = <0x37>;
							};

							ldo@18 {
								reg = <0x12>;
								regulator-name = "vdd28";
								sprd,default-microvolt = <0x2ab980>;
								sprd,step-microvolt = <0x30d4>;
								regulator-min-microvolt = <0x189ad4>;
								regulator-max-microvolt = <0x30d400>;
								regulator-microvolt-offset = <0x0>;
								sprd,hide-offset = <0x3e8>;
							};

							ldo@19 {
								reg = <0x13>;
								regulator-name = "vddwifipa";
								sprd,default-microvolt = <0x325aa0>;
								sprd,step-microvolt = <0x30d4>;
								regulator-min-microvolt = <0x200b20>;
								regulator-max-microvolt = <0x38444c>;
								regulator-microvolt-offset = <0x0>;
								sprd,hide-offset = <0x3e8>;
								linux,phandle = <0xb0>;
								phandle = <0xb0>;
							};

							ldo@20 {
								reg = <0x14>;
								regulator-name = "vdddcxo";
								sprd,default-microvolt = <0x1b7740>;
								sprd,step-microvolt = <0x30d4>;
								regulator-min-microvolt = <0x16e360>;
								regulator-max-microvolt = <0x2f1c8c>;
								regulator-microvolt-offset = <0x0>;
								sprd,hide-offset = <0x3e8>;
							};

							ldo@21 {
								reg = <0x15>;
								regulator-name = "vddusb33";
								sprd,default-microvolt = <0x325aa0>;
								sprd,step-microvolt = <0x30d4>;
								regulator-min-microvolt = <0x200b20>;
								regulator-max-microvolt = <0x38444c>;
								regulator-microvolt-offset = <0x0>;
								sprd,hide-offset = <0x3e8>;
								linux,phandle = <0x3a>;
								phandle = <0x3a>;
							};
						};
					};

					poweroff@c20 {
						compatible = "sprd,sc2720-poweroff";
						reg = <0xc20>;
					};

					vibrator@e00 {
						compatible = "sprd,sc2721-vibrator";
						reg = <0xe00>;
					};

					charger@e0c {
						compatible = "sprd,sc2720-charger";
						reg = <0xe0c>;
						chg-cv-gpios = <0x31 0x4 0x0>;
						chg-ovi-gpios = <0x31 0x6 0x0>;
						status = "okay";
					};

					reset@e68 {
						compatible = "sprd,sc2720-7sreset";
						reg = <0xe68 0xe38>;
					};
				};
			};

			modem-dbg-log@40470000 {
				compatible = "sprd,dbg-log-sharkl2";
				reg = <0x40470000 0x1000 0x404a0000 0x1000>;
				sprd,syscon-aon-apb = <0x16>;
			};

			audio-codec@40000000 {
				compatible = "sprd,sharkl2-audio-codec";
				reg = <0x40000000 0x2000>;
				sprd,def-da-fs = <0xac44>;
				interrupts = <0x0 0x14 0x0>;
				sprd,syscon-aon-apb = <0x16>;
				linux,phandle = <0x4e>;
				phandle = <0x4e>;
			};

			vbc@40020000 {
				compatible = "sprd,vbc-r1p0v3";
				#sound-dai-cells = <0x1>;
				reg = <0x40020000 0x10000>;
				sprd,clk-stable = <0x402d0060 0x4>;
				sprd,syscon-aon-apb = <0x16>;
				sprd,syscon-pmu-apb = <0x4d>;
				sprd,dynamic-eq-support = <0x0>;
				sprd,vbc-iis-lr-invert = <0x0 0x1 0x1>;
				sprd,vbc-use-dma-type = <0x0 0x0 0x1 0x1>;
				sprd,iis_not_set_same_num = <0x1>;
				sprd,vbc-use-ad01-only = <0x1>;
				pinctrl-names = "ap_iis0_0", "pubcp_iis0_0", "tgdsp_iis0_0", "vbc_iis2_0", "ap_iis0_1", "pubcp_iis0_1", "tgdsp_iis0_1", "vbc_iis1_1";
				pinctrl-0 = <0x4f>;
				pinctrl-1 = <0x50>;
				pinctrl-2 = <0x51>;
				pinctrl-3 = <0x52>;
				pinctrl-4 = <0x53>;
				pinctrl-5 = <0x54>;
				pinctrl-6 = <0x55>;
				pinctrl-7 = <0x56>;
				linux,phandle = <0xa8>;
				phandle = <0xa8>;
			};
		};

		mm {
			compatible = "simple-bus";
			#address-cells = <0x1>;
			#size-cells = <0x1>;
			ranges;

			mipi-csi-phy0 {
				compatible = "sprd,mipi-csi-phy";
				sprd,phyid = <0x0>;
				status = "okay";
				sprd,phycfg = <0x0>;
				sprd,csi = <0x57>;

				port {

					endpoint {
						remote-endpoint = <0x58 0x59>;
						linux,phandle = <0x26>;
						phandle = <0x26>;
					};
				};
			};

			mipi-csi-phy1 {
				compatible = "sprd,mipi-csi-phy";
				sprd,phyid = <0x1>;
				status = "disabled";
			};

			mipi-csi-phy2 {
				compatible = "sprd,mipi-csi-phy";
				sprd,phyid = <0x2>;
				status = "disabled";
			};

			gpu@60000000 {
				compatible = "sprd,mali-midgard";
				reg = <0x60000000 0x4000>;
				gpu-supply = <0x5a>;
				sprd,syscon-aon-apb = <0x16>;
				sprd,syscon-pmu-apb = <0x4d>;
				sprd,syscon-gpu-ahb = <0x5b>;
				interrupts = <0x0 0x27 0x4 0x0 0x27 0x4 0x0 0x27 0x4>;
				interrupt-names = "JOB", "MMU", "GPU";
				clocks = <0x44 0x1b 0x5c 0x3b 0x5d 0x5e 0x5f 0x33 0xe 0x49>;
				operating-points = <0x25800 0xdbba0 0x3e800 0xdbba0 0x5dc00 0xdbba0 0x82208 0xdbba0 0x927c0 0xf4240>;
				sprd,dfs-lists = <0x25800 0xdbba0 0x2 0x1 0x3e800 0xdbba0 0x4 0x1 0x5dc00 0xdbba0 0x6 0x1 0x82208 0xdbba0 0x8 0x1 0x927c0 0xf4240 0x8 0x1>;
				sprd,dfs-default = <0x1>;
				sprd,dfs-scene-extreme = <0x3>;
				sprd,dfs-scene-high = <0x2>;
				sprd,dfs-scene-medium = <0x1>;
				sprd,dfs-scene-low = <0x0>;
				sprd,dfs-range-max = <0x4>;
				sprd,dfs-range-min = <0x0>;
			};

			dcam@60800000 {
				compatible = "sprd,dcam";
				reg = <0x60800000 0x4000>;
				interrupts = <0x0 0x2d 0x4>;
				sprd,cam-ahb-syscon = <0x60>;
				sprd,aon-apb-syscon = <0x16>;
				sprd,syscon-pmu-apb = <0x4d>;
				sprd,isp = <0x61>;
				sprd,dcam-count = <0x1>;
				iommus = <0x62>;
				status = "okay";
				clock-names = "dcam_eb", "clk_gate_eb", "dcam_axi_eb", "clk_mm_eb", "clk_mm_ahb", "clk_mm_ahb_parent", "dcam_clk", "dcam_clk_parent", "dcam_axi_clk", "dcam_axi_clk_parent";
				clocks = <0x63 0x0 0x63 0x5 0x1d 0x3 0x44 0x19 0x64 0x3b 0x65 0x5f 0x66 0xe>;
			};

			iommu@60800040 {
				compatible = "sprd,iommuexpk2-dcam";
				reg = <0x60800040 0x4 0x60800200 0x60 0x40000000 0x10000000>;
				reg_name = "mmu_interrupt_reg", "mmu_reg", "iova pool";
				status = "okay";
				#iommu-cells = <0x0>;
				linux,phandle = <0x62>;
				phandle = <0x62>;
			};

			video-codec@60900000 {
				compatible = "sprd,pike2-vsp";
				reg = <0x60900000 0xc000>;
				interrupts = <0x0 0x2b 0x4>;
				sprd,syscon-pmu-apb = <0x4d>;
				sprd,syscon-aon-apb = <0x16>;
				sprd,syscon-mm-ahb = <0x60>;
				iommus = <0x67>;
				status = "ok";
				clock-names = "clk_mm_eb", "clk_vsp_mq_ahb_eb", "clk_axi_gate_vsp", "clk_ahb_gate_vsp_eb", "clk_vsp";
				clocks = <0x45 0xe 0x63 0x6 0x63 0x5 0x63 0x2 0x68>;
			};

			iommu@60901004 {
				compatible = "sprd,iommuexpk2-vsp";
				reg = <0x60901004 0x4 0x60901140 0x60 0x20000000 0x10000000>;
				reg_name = "mmu_interrupt_reg", "mmu_reg", "iova pool";
				status = "okay";
				#iommu-cells = <0x0>;
				linux,phandle = <0x67>;
				phandle = <0x67>;
			};

			isp@60a00000 {
				compatible = "sprd,isp";
				reg = <0x60a00000 0x100000>;
				interrupts = <0x0 0x2c 0x4 0x0 0x7d 0x4>;
				sprd,cam-ahb-syscon = <0x60>;
				sprd,aon-apb-syscon = <0x16>;
				sprd,isp-count = <0x1>;
				iommus = <0x69>;
				status = "okay";
				clock-names = "isp_eb", "isp_axi_eb", "isp_clk", "isp_clk_high_parent", "isp_clk_low_parent", "isp_axi_clk", "isp_axi_clk_parent";
				clocks = <0x63 0x1 0x1d 0x2 0x6a 0x5f 0x6b 0x6c 0xe>;
				linux,phandle = <0x61>;
				phandle = <0x61>;
			};

			iommu@60a00800 {
				compatible = "sprd,iommuexpk2-isp";
				reg = <0x0 0x40000 0x60a00800 0x400 0x50000000 0x10000000>;
				reg_name = "mmu_interrupt_reg", "mmu_reg", "iova pool";
				status = "okay";
				#iommu-cells = <0x0>;
				linux,phandle = <0x69>;
				phandle = <0x69>;
			};

			jpeg-codec@60b00000 {
				compatible = "sprd,pike2-jpg";
				reg = <0x60b00000 0x8000>;
				interrupts = <0x0 0x2a 0x4>;
				sprd,syscon-pmu-apb = <0x4d>;
				sprd,syscon-aon-apb = <0x16>;
				sprd,syscon-mm-ahb = <0x60>;
				iommus = <0x6d>;
				status = "okay";
				clock-names = "clk_mm_eb", "clk_vsp_mq_ahb_eb", "clk_axi_gate_jpg", "clk_ahb_gate_jpg_eb", "clk_jpg";
				clocks = <0x45 0xe 0x63 0x6 0x63 0x5 0x63 0x4 0x6e>;
			};

			iommu@60b00024 {
				compatible = "sprd,iommuexpk2-jpg";
				reg = <0x60b00024 0x4 0x60b00100 0x400 0x70000000 0x10000000>;
				reg_name = "mmu_interrupt_reg", "mmu_reg", "iova pool";
				status = "okay";
				#iommu-cells = <0x0>;
				linux,phandle = <0x6d>;
				phandle = <0x6d>;
			};

			csi@60c00000 {
				compatible = "sprd,csi-controller";
				reg = <0x60c00000 0x1000>;
				interrupts = <0x0 0x28 0x4 0x0 0x29 0x4>;
				sprd,cam-ahb-syscon = <0x60>;
				sprd,ana-apb-syscon = <0x16>;
				sprd,csi-id = <0x0>;
				sprd,ip-version = <0x100>;
				status = "okay";
				clock-names = "clk_mipi_csi_gate_eb", "clk_csi_eb", "clk_cphy_cfg_gate_eb", "mipi_csi_src_eb";
				clocks = <0x63 0x3 0x1d 0x4 0x1d 0x0 0x6f 0x10>;
				linux,phandle = <0x57>;
				phandle = <0x57>;
			};

			cpp@61000000 {
				compatible = "sprd,cpp";
				reg = <0x61000000 0x1000>;
				interrupts = <0x0 0x7e 0x4>;
				sprd,cam-ahb-syscon = <0x60>;
				sprd,ana-apb-syscon = <0x16>;
				iommus = <0x70>;
				status = "disable";
			};

			iommu@61000010 {
				compatible = "sprd,iommuex-cpp";
				reg = <0x61000010 0x4 0x61000200 0x60 0x60000000 0x8000000>;
				reg_name = "mmu_interrupt_reg", "mmu_reg", "iova pool";
				status = "disabled";
				#iommu-cells = <0x0>;
				linux,phandle = <0x70>;
				phandle = <0x70>;
			};

			csi@61200000 {
				compatible = "sprd,csi-controller";
				reg = <0x61200000 0x1000>;
				interrupts = <0x0 0x47 0x4 0x0 0x48 0x4>;
				sprd,cam-ahb-syscon = <0x60>;
				sprd,ana-apb-syscon = <0x16>;
				sprd,csi-id = <0x1>;
				sprd,ip-version = <0x100>;
				status = "disable";
			};
		};

		ext-26m {
			compatible = "fixed-clock";
			#clock-cells = <0x0>;
			clock-frequency = <0x18cba80>;
			clock-output-names = "ext_26m";
			linux,phandle = <0x3>;
			phandle = <0x3>;
		};

		ext-26m-cp {
			compatible = "fixed-clock";
			#clock-cells = <0x0>;
			clock-frequency = <0x18cba80>;
			clock-output-names = "ext_26m_cp";
			linux,phandle = <0x85>;
			phandle = <0x85>;
		};

		ext-26m-aud {
			compatible = "fixed-clock";
			#clock-cells = <0x0>;
			clock-frequency = <0x18cba80>;
			clock-output-names = "ext_26m_aud";
			linux,phandle = <0x89>;
			phandle = <0x89>;
		};

		ext-32k {
			compatible = "fixed-clock";
			#clock-cells = <0x0>;
			clock-frequency = <0x8000>;
			clock-output-names = "ext_32k";
			linux,phandle = <0x84>;
			phandle = <0x84>;
		};

		ext-26m-rf1 {
			compatible = "fixed-clock";
			#clock-cells = <0x0>;
			clock-frequency = <0x18cba80>;
			clock-output-names = "ext_26m_rf1";
		};

		ext-1m {
			compatible = "fixed-clock";
			#clock-cells = <0x0>;
			clock-frequency = <0xf4240>;
			clock-output-names = "ext_1m";
			linux,phandle = <0x8e>;
			phandle = <0x8e>;
		};

		ext-2m {
			compatible = "fixed-clock";
			#clock-cells = <0x0>;
			clock-frequency = <0x1e8480>;
			clock-output-names = "ext_2m";
		};

		ext-4m {
			compatible = "fixed-clock";
			#clock-cells = <0x0>;
			clock-frequency = <0x3d0900>;
			clock-output-names = "ext_4m";
		};

		ext-6m5 {
			compatible = "fixed-clock";
			#clock-cells = <0x0>;
			clock-frequency = <0x632ea0>;
			clock-output-names = "ext_6m5";
			linux,phandle = <0x8c>;
			phandle = <0x8c>;
		};

		ext-13m {
			compatible = "fixed-clock";
			#clock-cells = <0x0>;
			clock-frequency = <0xc65d40>;
			clock-output-names = "ext_13m";
			linux,phandle = <0x8d>;
			phandle = <0x8d>;
		};

		ext-250k {
			compatible = "fixed-clock";
			#clock-cells = <0x0>;
			clock-frequency = <0x3d090>;
			clock-output-names = "ext_250k";
			linux,phandle = <0x87>;
			phandle = <0x87>;
		};

		clk-pad {
			compatible = "fixed-clock";
			#clock-cells = <0x0>;
			clock-frequency = <0x3d09000>;
			clock-output-names = "clk_pad";
		};

		clk@402e0014 {
			compatible = "sprd,sc1000-gates-clock";
			#clock-cells = <0x1>;
			sprd,gates-msk = <0x200>;
			reg = <0x402e0014 0x3000>;
			clocks = <0x3>;
			clock-output-names = "clk_audio_gate";
		};

		clk@402b0088 {
			compatible = "sprd,sc1000-hppll-gates-clock";
			#clock-cells = <0x1>;
			sprd,gates-msk = <0x1>;
			reg = <0x402b0088 0x3000>;
			clocks = <0x3>;
			clock-output-names = "clk_cpll_gate";
			linux,phandle = <0x73>;
			phandle = <0x73>;
		};

		clk@402b0090 {
			compatible = "sprd,sc1000-hppll-gates-clock";
			#clock-cells = <0x1>;
			sprd,gates-msk = <0x1>;
			reg = <0x402b0090 0x3000>;
			clocks = <0x3>;
			clock-output-names = "clk_gpll_gate";
			linux,phandle = <0x74>;
			phandle = <0x74>;
		};

		clk@402b0094 {
			compatible = "sprd,sc1000-hppll-gates-clock";
			#clock-cells = <0x1>;
			sprd,gates-msk = <0x1>;
			reg = <0x402b0094 0x3000>;
			clocks = <0x3>;
			clock-output-names = "clk_mpll_gate";
			linux,phandle = <0x71>;
			phandle = <0x71>;
		};

		clk@402b0098 {
			compatible = "sprd,sc1000-hppll-gates-clock";
			#clock-cells = <0x1>;
			sprd,gates-msk = <0x1>;
			reg = <0x402b0098 0x3000>;
			clocks = <0x3>;
			clock-output-names = "clk_dpll_gate";
			linux,phandle = <0x72>;
			phandle = <0x72>;
		};

		clk@402b0344 {
			compatible = "sprd,sc1000-hppll-gates-clock";
			#clock-cells = <0x1>;
			sprd,gates-msk = <0x4>;
			reg = <0x402b0344 0x3000>;
			clocks = <0x3>;
			clock-output-names = "clk_bbpll_gate";
			linux,phandle = <0x75>;
			phandle = <0x75>;
		};

		clk@402e0044 {
			compatible = "sprd,sc7731e-adjustable-pll-clock";
			#clock-cells = <0x0>;
			reg = <0x402e0044 0x4 0x402e0048 0x4>;
			clocks = <0x71 0x0>;
			clock-output-names = "clk_mpll";
			linux,phandle = <0x79>;
			phandle = <0x79>;
		};

		clk@402e004c {
			compatible = "sprd,sc7731e-adjustable-pll-clock";
			#clock-cells = <0x0>;
			reg = <0x402e004c 0x4 0x402e0050 0x4>;
			clocks = <0x72 0x0>;
			clock-output-names = "clk_dpll";
			linux,phandle = <0x47>;
			phandle = <0x47>;
		};

		clk@402e0054 {
			compatible = "sprd,sc7731e-adjustable-pll-clock";
			#clock-cells = <0x0>;
			reg = <0x402e0054 0x4 0x402e0058 0x4>;
			clocks = <0x3>;
			clock-output-names = "clk_twpll";
			linux,phandle = <0x76>;
			phandle = <0x76>;
		};

		clk@402e0150 {
			compatible = "sprd,sc7731e-adjustable-pll-clock";
			#clock-cells = <0x0>;
			reg = <0x402e0150 0x4 0x402e0154 0x4>;
			clocks = <0x73 0x0>;
			clock-output-names = "clk_cpll";
			linux,phandle = <0x48>;
			phandle = <0x48>;
		};

		clk@402e0158 {
			compatible = "sprd,sc7731e-adjustable-pll-clock";
			#clock-cells = <0x0>;
			reg = <0x402e0158 0x4 0x402e015c 0x4>;
			clocks = <0x74 0x0>;
			clock-output-names = "clk_gpll";
			linux,phandle = <0x49>;
			phandle = <0x49>;
		};

		clk-bbpll {
			compatible = "fixed-clock";
			#clock-cells = <0x0>;
			clock-frequency = <0x4a62f800>;
			clocks = <0x75 0x2>;
			clock-output-names = "clk_bbpll";
			linux,phandle = <0x77>;
			phandle = <0x77>;
		};

		clk-twpll-768m {
			compatible = "fixed-factor-clock";
			#clock-cells = <0x0>;
			clock-mult = <0x1>;
			clock-div = <0x2>;
			clocks = <0x76>;
			clock-output-names = "clk_twpll_768m";
			linux,phandle = <0x78>;
			phandle = <0x78>;
		};

		clk-twpll-384m {
			compatible = "fixed-factor-clock";
			#clock-cells = <0x0>;
			clock-mult = <0x1>;
			clock-div = <0x4>;
			clocks = <0x76>;
			clock-output-names = "clk_twpll_384m";
			linux,phandle = <0x33>;
			phandle = <0x33>;
		};

		clk-twpll-192m {
			compatible = "fixed-factor-clock";
			#clock-cells = <0x0>;
			clock-mult = <0x1>;
			clock-div = <0x8>;
			clocks = <0x76>;
			clock-output-names = "clk_twpll_192m";
			linux,phandle = <0x5d>;
			phandle = <0x5d>;
		};

		clk-twpll-96m {
			compatible = "fixed-factor-clock";
			#clock-cells = <0x0>;
			clock-mult = <0x1>;
			clock-div = <0x10>;
			clocks = <0x76>;
			clock-output-names = "clk_twpll_96m";
			linux,phandle = <0x1e>;
			phandle = <0x1e>;
		};

		clk-twpll-48m {
			compatible = "fixed-factor-clock";
			#clock-cells = <0x0>;
			clock-mult = <0x1>;
			clock-div = <0x20>;
			clocks = <0x76>;
			clock-output-names = "clk_twpll_48m";
			linux,phandle = <0x20>;
			phandle = <0x20>;
		};

		clk-twpll-24m {
			compatible = "fixed-factor-clock";
			#clock-cells = <0x0>;
			clock-mult = <0x1>;
			clock-div = <0x40>;
			clocks = <0x76>;
			clock-output-names = "clk_twpll_24m";
		};

		clk-twpll-12m {
			compatible = "fixed-factor-clock";
			#clock-cells = <0x0>;
			clock-mult = <0x1>;
			clock-div = <0x80>;
			clocks = <0x76>;
			clock-output-names = "clk_twpll_12m";
		};

		clk-twpll-512m {
			compatible = "fixed-factor-clock";
			#clock-cells = <0x0>;
			clock-mult = <0x1>;
			clock-div = <0x3>;
			clocks = <0x76>;
			clock-output-names = "clk_twpll_512m";
			linux,phandle = <0xe>;
			phandle = <0xe>;
		};

		clk-twpll-256m {
			compatible = "fixed-factor-clock";
			#clock-cells = <0x0>;
			clock-mult = <0x1>;
			clock-div = <0x6>;
			clocks = <0x76>;
			clock-output-names = "clk_twpll_256m";
			linux,phandle = <0x5e>;
			phandle = <0x5e>;
		};

		clk-twpll-170m7 {
			compatible = "fixed-factor-clock";
			#clock-cells = <0x0>;
			clock-mult = <0x1>;
			clock-div = <0x9>;
			clocks = <0x76>;
			clock-output-names = "clk_twpll_170m7";
			linux,phandle = <0x91>;
			phandle = <0x91>;
		};

		clk-twpll-128m {
			compatible = "fixed-factor-clock";
			#clock-cells = <0x0>;
			clock-mult = <0x1>;
			clock-div = <0xc>;
			clocks = <0x76>;
			clock-output-names = "clk_twpll_128m";
			linux,phandle = <0x6b>;
			phandle = <0x6b>;
		};

		clk-twpll-64m {
			compatible = "fixed-factor-clock";
			#clock-cells = <0x0>;
			clock-mult = <0x1>;
			clock-div = <0x18>;
			clocks = <0x76>;
			clock-output-names = "clk_twpll_64m";
			linux,phandle = <0x7d>;
			phandle = <0x7d>;
		};

		clk-twpll-307m2 {
			compatible = "fixed-factor-clock";
			#clock-cells = <0x0>;
			clock-mult = <0x1>;
			clock-div = <0x5>;
			clocks = <0x76>;
			clock-output-names = "clk_twpll_307m2";
			linux,phandle = <0x5f>;
			phandle = <0x5f>;
		};

		clk-twpll-153m6 {
			compatible = "fixed-factor-clock";
			#clock-cells = <0x0>;
			clock-mult = <0x1>;
			clock-div = <0xa>;
			clocks = <0x76>;
			clock-output-names = "clk_twpll_153m6";
			linux,phandle = <0x3b>;
			phandle = <0x3b>;
		};

		clk-twpll-76m8 {
			compatible = "fixed-factor-clock";
			#clock-cells = <0x0>;
			clock-mult = <0x1>;
			clock-div = <0x14>;
			clocks = <0x76>;
			clock-output-names = "clk_twpll_76m8";
			linux,phandle = <0x1f>;
			phandle = <0x1f>;
		};

		clk-twpll-51m2 {
			compatible = "fixed-factor-clock";
			#clock-cells = <0x0>;
			clock-mult = <0x1>;
			clock-div = <0x1e>;
			clocks = <0x76>;
			clock-output-names = "clk_twpll_51m2";
			linux,phandle = <0x81>;
			phandle = <0x81>;
		};

		clk-twpll-38m4 {
			compatible = "fixed-factor-clock";
			#clock-cells = <0x0>;
			clock-mult = <0x1>;
			clock-div = <0x28>;
			clocks = <0x76>;
			clock-output-names = "clk_twpll_38m4";
			linux,phandle = <0x8a>;
			phandle = <0x8a>;
		};

		clk-twpll-19m2 {
			compatible = "fixed-factor-clock";
			#clock-cells = <0x0>;
			clock-mult = <0x1>;
			clock-div = <0x50>;
			clocks = <0x76>;
			clock-output-names = "clk_twpll_19m2";
		};

		clk-twpll-219m4 {
			compatible = "fixed-factor-clock";
			#clock-cells = <0x0>;
			clock-mult = <0x1>;
			clock-div = <0x7>;
			clocks = <0x76>;
			clock-output-names = "clk_twpll_219m4";
			linux,phandle = <0x92>;
			phandle = <0x92>;
		};

		clk-cpll-800m {
			compatible = "fixed-factor-clock";
			#clock-cells = <0x0>;
			clock-mult = <0x1>;
			clock-div = <0x2>;
			clocks = <0x48>;
			clock-output-names = "clk_cpll_800m";
			linux,phandle = <0x82>;
			phandle = <0x82>;
		};

		clk-cpll-533m {
			compatible = "fixed-factor-clock";
			#clock-cells = <0x0>;
			clock-mult = <0x1>;
			clock-div = <0x3>;
			clocks = <0x48>;
			clock-output-names = "clk_cpll_533m";
			linux,phandle = <0x95>;
			phandle = <0x95>;
		};

		clk-cpll-400m {
			compatible = "fixed-factor-clock";
			#clock-cells = <0x0>;
			clock-mult = <0x1>;
			clock-div = <0x4>;
			clocks = <0x48>;
			clock-output-names = "clk_cpll_400m";
			linux,phandle = <0x8f>;
			phandle = <0x8f>;
		};

		clk-cpll-320m {
			compatible = "fixed-factor-clock";
			#clock-cells = <0x0>;
			clock-mult = <0x1>;
			clock-div = <0x5>;
			clocks = <0x48>;
			clock-output-names = "clk_cpll_320m";
			linux,phandle = <0x7f>;
			phandle = <0x7f>;
		};

		clk-cpll-266m67 {
			compatible = "fixed-factor-clock";
			#clock-cells = <0x0>;
			clock-mult = <0x1>;
			clock-div = <0x6>;
			clocks = <0x48>;
			clock-output-names = "clk_cpll_266m67";
			linux,phandle = <0x7b>;
			phandle = <0x7b>;
		};

		clk-cpll-228m57 {
			compatible = "fixed-factor-clock";
			#clock-cells = <0x0>;
			clock-mult = <0x1>;
			clock-div = <0x7>;
			clocks = <0x48>;
			clock-output-names = "clk_cpll_228m57";
			linux,phandle = <0x93>;
			phandle = <0x93>;
		};

		clk-cpll-200m {
			compatible = "fixed-factor-clock";
			#clock-cells = <0x0>;
			clock-mult = <0x1>;
			clock-div = <0x8>;
			clocks = <0x48>;
			clock-output-names = "clk_cpll_200m";
			linux,phandle = <0x7c>;
			phandle = <0x7c>;
		};

		clk-cpll-160m {
			compatible = "fixed-factor-clock";
			#clock-cells = <0x0>;
			clock-mult = <0x1>;
			clock-div = <0xa>;
			clocks = <0x48>;
			clock-output-names = "clk_cpll_160m";
			linux,phandle = <0x94>;
			phandle = <0x94>;
		};

		clk-cpll-133m34 {
			compatible = "fixed-factor-clock";
			#clock-cells = <0x0>;
			clock-mult = <0x1>;
			clock-div = <0xc>;
			clocks = <0x48>;
			clock-output-names = "clk_cpll_133m34";
			linux,phandle = <0x88>;
			phandle = <0x88>;
		};

		clk-cpll-100m {
			compatible = "fixed-factor-clock";
			#clock-cells = <0x0>;
			clock-mult = <0x1>;
			clock-div = <0x10>;
			clocks = <0x48>;
			clock-output-names = "clk_cpll_100m";
			linux,phandle = <0x7e>;
			phandle = <0x7e>;
		};

		clk-cpll-50m {
			compatible = "fixed-factor-clock";
			#clock-cells = <0x0>;
			clock-mult = <0x1>;
			clock-div = <0x20>;
			clocks = <0x48>;
			clock-output-names = "clk_cpll_50m";
			linux,phandle = <0x83>;
			phandle = <0x83>;
		};

		clk-cpll-40m {
			compatible = "fixed-factor-clock";
			#clock-cells = <0x0>;
			clock-mult = <0x1>;
			clock-div = <0x28>;
			clocks = <0x48>;
			clock-output-names = "clk_cpll_40m";
			linux,phandle = <0x86>;
			phandle = <0x86>;
		};

		clk-bbpll-416m {
			compatible = "fixed-factor-clock";
			#clock-cells = <0x0>;
			clock-mult = <0x1>;
			clock-div = <0x3>;
			clocks = <0x77>;
			clock-output-names = "clk_bbpll_416m";
			linux,phandle = <0x90>;
			phandle = <0x90>;
		};

		clk-mcu {
			compatible = "sprd,composite-clock";
			#clock-cells = <0x0>;
			reg = <0x20e00054 0x4 0x20e00038 0x4>;
			sprd,mux-msk = <0x7>;
			sprd,div-msk = <0x70>;
			clocks = <0x3 0xe 0x78 0x47 0x48 0x76 0x79>;
			clock-output-names = "clk_mcu";
			linux,phandle = <0x7a>;
			phandle = <0x7a>;
		};

		clk-ca7-axi {
			compatible = "sprd,divider-clock";
			#clock-cells = <0x0>;
			sprd,div-msk = <0x700>;
			clocks = <0x7a>;
			clock-output-names = "clk_ca7_axi";
			linux,phandle = <0xa0>;
			phandle = <0xa0>;
		};

		clk-ca7-dbg {
			compatible = "sprd,divider-clock";
			#clock-cells = <0x0>;
			sprd,div-msk = <0x70000>;
			clocks = <0x7a>;
			clock-output-names = "clk_ca7_dbg";
			linux,phandle = <0xa1>;
			phandle = <0xa1>;
		};

		clk@21500020 {
			compatible = "sprd,muxed-clock";
			#clock-cells = <0x0>;
			reg = <0x21500020 0x4>;
			sprd,mux-msk = <0x7>;
			clocks = <0x3 0x1f 0x6b 0x5e 0x7b>;
			clock-output-names = "clk_ap_axi";
			linux,phandle = <0x96>;
			phandle = <0x96>;
		};

		clk@21500024 {
			compatible = "sprd,muxed-clock";
			#clock-cells = <0x0>;
			reg = <0x21500024 0x4>;
			sprd,mux-msk = <0x7>;
			clocks = <0x3 0x1f 0x6b 0x5d 0x7c>;
			clock-output-names = "clk_ap_ahb";
			linux,phandle = <0x80>;
			phandle = <0x80>;
		};

		clk@21500028 {
			compatible = "sprd,muxed-clock";
			#clock-cells = <0x0>;
			reg = <0x21500028 0x4>;
			sprd,mux-msk = <0x7>;
			clocks = <0x3 0x7d 0x1e 0x7e 0x6b>;
			clock-output-names = "clk_ap_apb";
			linux,phandle = <0x97>;
			phandle = <0x97>;
		};

		clk@2150002c {
			compatible = "sprd,muxed-clock";
			#clock-cells = <0x0>;
			reg = <0x2150002c 0x4>;
			sprd,mux-msk = <0x7>;
			clocks = <0x3b 0x5e 0x5f 0x7f 0x33>;
			clock-output-names = "clk_gsp";
			linux,phandle = <0x39>;
			phandle = <0x39>;
		};

		clk@21500030 {
			compatible = "sprd,muxed-clock";
			#clock-cells = <0x0>;
			reg = <0x21500030 0x4>;
			sprd,mux-msk = <0x7>;
			clocks = <0x6b 0x3b 0x5d 0x5e 0x7f 0x33>;
			clock-output-names = "clk_dispc0";
			linux,phandle = <0x3c>;
			phandle = <0x3c>;
		};

		clk@21500034 {
			compatible = "sprd,composite-clock";
			#clock-cells = <0x0>;
			reg = <0x21500034 0x4>;
			sprd,mux-msk = <0x7>;
			sprd,div-msk = <0xf00>;
			clocks = <0x1e 0x7e 0x6b 0x3b 0x5d>;
			clock-output-names = "clk_dispc0_dpi";
			linux,phandle = <0x3d>;
			phandle = <0x3d>;
		};

		clk@21500038 {
			compatible = "sprd,gates-clock";
			#clock-cells = <0x1>;
			reg = <0x21500038 0x4>;
			sprd,gates-msk = <0x10000>;
			clocks = <0x80>;
			clock-output-names = "clk_dsi_rxsec";
		};

		clk@2150003c {
			compatible = "sprd,gates-clock";
			#clock-cells = <0x1>;
			reg = <0x2150003c 0x4>;
			sprd,gates-msk = <0x10000>;
			clocks = <0x80>;
			clock-output-names = "clk_dlanebyte";
		};

		clk@2150004c {
			compatible = "sprd,gates-clock";
			#clock-cells = <0x1>;
			reg = <0x2150004c 0x4>;
			sprd,gates-msk = <0x10000>;
			clocks = <0x80>;
			clock-output-names = "clk_otg_utmi";
		};

		clk@21500050 {
			compatible = "sprd,composite-clock";
			#clock-cells = <0x0>;
			reg = <0x21500050 0x4>;
			sprd,mux-msk = <0x3>;
			sprd,div-msk = <0x700>;
			clocks = <0x3 0x20 0x81 0x1e>;
			clock-output-names = "clk_uart0";
			linux,phandle = <0x18>;
			phandle = <0x18>;
		};

		clk@21500054 {
			compatible = "sprd,composite-clock";
			#clock-cells = <0x0>;
			reg = <0x21500054 0x4>;
			sprd,mux-msk = <0x3>;
			sprd,div-msk = <0x700>;
			clocks = <0x3 0x20 0x81 0x1e>;
			clock-output-names = "clk_uart1";
			linux,phandle = <0x1a>;
			phandle = <0x1a>;
		};

		clk@21500058 {
			compatible = "sprd,composite-clock";
			#clock-cells = <0x0>;
			reg = <0x21500058 0x4>;
			sprd,mux-msk = <0x3>;
			sprd,div-msk = <0x700>;
			clocks = <0x3 0x20 0x81 0x3b>;
			clock-output-names = "clk_i2c0";
			linux,phandle = <0x1b>;
			phandle = <0x1b>;
		};

		clk@2150005c {
			compatible = "sprd,composite-clock";
			#clock-cells = <0x0>;
			reg = <0x2150005c 0x4>;
			sprd,mux-msk = <0x3>;
			sprd,div-msk = <0x700>;
			clocks = <0x3 0x20 0x81 0x3b>;
			clock-output-names = "clk_i2c1";
			linux,phandle = <0x27>;
			phandle = <0x27>;
		};

		clk@21500060 {
			compatible = "sprd,composite-clock";
			#clock-cells = <0x0>;
			reg = <0x21500060 0x4>;
			sprd,mux-msk = <0x3>;
			sprd,div-msk = <0x700>;
			clocks = <0x3 0x20 0x81 0x3b>;
			clock-output-names = "clk_i2c2";
			linux,phandle = <0x28>;
			phandle = <0x28>;
		};

		clk@21500064 {
			compatible = "sprd,composite-clock";
			#clock-cells = <0x0>;
			reg = <0x21500064 0x4>;
			sprd,mux-msk = <0x7>;
			sprd,div-msk = <0x700>;
			clocks = <0x3 0x7e 0x6b 0x3b 0x5d>;
			clock-output-names = "clk_spi0";
			linux,phandle = <0x2a>;
			phandle = <0x2a>;
		};

		clk@21500068 {
			compatible = "sprd,composite-clock";
			#clock-cells = <0x0>;
			reg = <0x21500068 0x4>;
			sprd,mux-msk = <0x3>;
			sprd,div-msk = <0x700>;
			clocks = <0x3 0x6b 0x3b>;
			clock-output-names = "clk_iis0";
			linux,phandle = <0xa2>;
			phandle = <0xa2>;
		};

		clk@2150006c {
			compatible = "sprd,muxed-clock";
			#clock-cells = <0x0>;
			reg = <0x2150006c 0x4>;
			sprd,mux-msk = <0x7>;
			clocks = <0x3 0x1e 0x7e 0x5d 0x5e>;
			clock-output-names = "clk_ce";
			linux,phandle = <0xa3>;
			phandle = <0xa3>;
		};

		clk@21500078 {
			compatible = "sprd,muxed-clock";
			#clock-cells = <0x0>;
			reg = <0x21500078 0x4>;
			sprd,mux-msk = <0x3>;
			clocks = <0x3 0x7c 0x5e 0x5f>;
			clock-output-names = "clk_nand_ecc";
			linux,phandle = <0xa4>;
			phandle = <0xa4>;
		};

		clk@402d0220 {
			compatible = "sprd,composite-clock";
			#clock-cells = <0x0>;
			reg = <0x402d0220 0x4>;
			sprd,mux-msk = <0x7>;
			sprd,div-msk = <0x300>;
			clocks = <0x3 0x33 0xe 0x78 0x82 0x47>;
			clock-output-names = "clk_emc_4x";
		};

		clk@402d0230 {
			compatible = "sprd,composite-clock";
			#clock-cells = <0x0>;
			reg = <0x402d0230 0x4>;
			sprd,mux-msk = <0x3>;
			sprd,div-msk = <0x300>;
			clocks = <0x3 0x7e 0x6b>;
			clock-output-names = "clk_aon_apb";
			linux,phandle = <0x8b>;
			phandle = <0x8b>;
		};

		clk@402d0234 {
			compatible = "sprd,muxed-clock";
			#clock-cells = <0x0>;
			reg = <0x402d0234 0x4>;
			sprd,mux-msk = <0x3>;
			clocks = <0x3 0x83 0x81>;
			clock-output-names = "clk_adi";
		};

		clk@402e0088 {
			compatible = "sprd,composite-clock";
			#clock-cells = <0x0>;
			reg = <0x402e0088 0x4>;
			sprd,mux-msk = <0x3>;
			sprd,div-msk = <0xf0000>;
			clocks = <0x84 0x85 0x3>;
			clock-output-names = "clk_aux0";
		};

		clk@402d0248 {
			compatible = "sprd,muxed-clock";
			#clock-cells = <0x0>;
			reg = <0x402d0248 0x4>;
			sprd,mux-msk = <0x7>;
			clocks = <0x84 0x85 0x3 0x86 0x20>;
			clock-output-names = "clk_pwm0";
		};

		clk@402d024c {
			compatible = "sprd,muxed-clock";
			#clock-cells = <0x0>;
			reg = <0x402d024c 0x4>;
			sprd,mux-msk = <0x7>;
			clocks = <0x84 0x85 0x3 0x86 0x20>;
			clock-output-names = "clk_pwm1";
			linux,phandle = <0x46>;
			phandle = <0x46>;
		};

		clk@402d0250 {
			compatible = "sprd,muxed-clock";
			#clock-cells = <0x0>;
			reg = <0x402d0250 0x4>;
			sprd,mux-msk = <0x7>;
			clocks = <0x84 0x85 0x3 0x86 0x20>;
			clock-output-names = "clk_pwm2";
		};

		clk@402d0254 {
			compatible = "sprd,muxed-clock";
			#clock-cells = <0x0>;
			reg = <0x402d0254 0x4>;
			sprd,mux-msk = <0x7>;
			clocks = <0x84 0x85 0x3 0x86 0x20>;
			clock-output-names = "clk_pwm3";
		};

		clk@402d0268 {
			compatible = "sprd,muxed-clock";
			#clock-cells = <0x0>;
			reg = <0x402d0268 0x4>;
			sprd,mux-msk = <0x1>;
			clocks = <0x84 0x87>;
			clock-output-names = "clk_thm";
		};

		clk@402d026c {
			compatible = "sprd,muxed-clock";
			#clock-cells = <0x0>;
			reg = <0x402d026c 0x4>;
			sprd,mux-msk = <0x7>;
			clocks = <0x3 0x20 0x81 0x88 0x3b>;
			clock-output-names = "clk_i2c";
		};

		clk@402d0270 {
			compatible = "sprd,muxed-clock";
			#clock-cells = <0x0>;
			reg = <0x402d0270 0x4>;
			sprd,mux-msk = <0x7>;
			clocks = <0x3 0x20 0x83 0x81 0x1e>;
			clock-output-names = "clk_avs";
		};

		clk@402d0278 {
			compatible = "sprd,muxed-clock";
			#clock-cells = <0x0>;
			reg = <0x402d0278 0x4>;
			sprd,mux-msk = <0x3>;
			clocks = <0x89 0x8a 0x83 0x81>;
			clock-output-names = "clk_audif";
		};

		clk@402d0280 {
			compatible = "sprd,gates-clock";
			#clock-cells = <0x1>;
			reg = <0x402d0280 0x4>;
			sprd,gates-msk = <0x10000>;
			clocks = <0x8b>;
			clock-output-names = "clk_iis_da0";
		};

		clk@402d0284 {
			compatible = "sprd,gates-clock";
			#clock-cells = <0x1>;
			reg = <0x402d0284 0x4>;
			sprd,gates-msk = <0x10000>;
			clocks = <0x8b>;
			clock-output-names = "clk_iis0_ad0";
		};

		clk@402d0288 {
			compatible = "sprd,gates-clock";
			#clock-cells = <0x1>;
			reg = <0x402d0288 0x4>;
			sprd,gates-msk = <0x10000>;
			clocks = <0x8b>;
			clock-output-names = "clk_iis1_ad0";
		};

		clk@402d028c {
			compatible = "sprd,muxed-clock";
			#clock-cells = <0x0>;
			reg = <0x402d028c 0x4>;
			sprd,mux-msk = <0x3>;
			clocks = <0x89 0x1f 0x7e 0x3b>;
			clock-output-names = "clk_ca7_dap";
		};

		clk@402d0290 {
			compatible = "sprd,gates-clock";
			#clock-cells = <0x1>;
			reg = <0x402d0290 0x4>;
			sprd,gates-msk = <0x10000>;
			clocks = <0x8b>;
			clock-output-names = "clk_cdap_mtck";
		};

		clk@402d0294 {
			compatible = "sprd,muxed-clock";
			#clock-cells = <0x0>;
			reg = <0x402d0294 0x4>;
			sprd,mux-msk = <0x7>;
			clocks = <0x84 0x3 0x6b 0x88 0x3b>;
			clock-output-names = "clk_ca7_ts";
		};

		clk@402d0298 {
			compatible = "sprd,gates-clock";
			#clock-cells = <0x1>;
			reg = <0x402d0298 0x4>;
			sprd,gates-msk = <0x10000>;
			clocks = <0x8b>;
			clock-output-names = "clk_djtag_tck";
		};

		clk@402d02a8 {
			compatible = "sprd,muxed-clock";
			#clock-cells = <0x0>;
			reg = <0x402d02a8 0x4>;
			sprd,mux-msk = <0x3>;
			clocks = <0x8c 0x8d 0x3>;
			clock-output-names = "clk_emc_ref";
		};

		clk@402d02ac {
			compatible = "sprd,composite-clock";
			#clock-cells = <0x0>;
			reg = <0x402d02ac 0x4>;
			sprd,mux-msk = <0x7>;
			sprd,div-msk = <0x300>;
			clocks = <0x3 0x1e 0x6b 0x3b 0x7b 0x33 0xe>;
			clock-output-names = "clk_cssys";
			linux,phandle = <0xd>;
			phandle = <0xd>;
		};

		clk@402d02b0 {
			compatible = "sprd,divider-clock";
			#clock-cells = <0x0>;
			reg = <0x402d02b0 0x4>;
			sprd,div-msk = <0x100>;
			clocks = <0xd>;
			clock-output-names = "clk_cssys_ca7";
		};

		clk@402d02bc {
			compatible = "sprd,muxed-clock";
			#clock-cells = <0x0>;
			reg = <0x402d02bc 0x4>;
			sprd,mux-msk = <0x7>;
			clocks = <0x8e 0x3 0x5f 0x33 0x8f 0x90>;
			clock-output-names = "clk_sdio0_2x";
			linux,phandle = <0x35>;
			phandle = <0x35>;
		};

		clk@402d02c4 {
			compatible = "sprd,muxed-clock";
			#clock-cells = <0x0>;
			reg = <0x402d02c4 0x4>;
			sprd,mux-msk = <0x7>;
			clocks = <0x8e 0x3 0x3b 0x91 0x7c 0x92 0x93 0x7b>;
			clock-output-names = "clk_nandc_2x";
		};

		clk@402d02cc {
			compatible = "sprd,muxed-clock";
			#clock-cells = <0x0>;
			reg = <0x402d02cc 0x4>;
			sprd,mux-msk = <0x7>;
			clocks = <0x8e 0x3 0x5f 0x33 0x8f 0x90>;
			clock-output-names = "clk_emmc_2x";
			linux,phandle = <0x32>;
			phandle = <0x32>;
		};

		clk@402d02dc {
			compatible = "sprd,gates-clock";
			#clock-cells = <0x1>;
			reg = <0x402d02dc 0x4>;
			sprd,gates-msk = <0x10000>;
			clocks = <0x8b>;
			clock-output-names = "clk_dsi_test";
		};

		clk@402d02e0 {
			compatible = "sprd,composite-clock";
			#clock-cells = <0x0>;
			reg = <0x402d02e0 0x4>;
			sprd,mux-msk = <0x7>;
			sprd,div-msk = <0x700>;
			clocks = <0x3 0x6b 0x88 0x3b 0x5d>;
			clock-output-names = "clk_ap_hs_spi";
			linux,phandle = <0x2b>;
			phandle = <0x2b>;
		};

		clk@402d02e4 {
			compatible = "sprd,muxed-clock";
			#clock-cells = <0x0>;
			reg = <0x402d02e4 0x4>;
			sprd,mux-msk = <0x3>;
			clocks = <0x3 0x86 0x20>;
			clock-output-names = "clk_sdphy_apb";
		};

		clk@402d02f0 {
			compatible = "sprd,muxed-clock";
			#clock-cells = <0x0>;
			reg = <0x402d02f0 0x4>;
			sprd,mux-msk = <0x7>;
			clocks = <0x3 0x86 0x20>;
			clock-output-names = "clk_analog_apb";
		};

		clk@402d02f4 {
			compatible = "sprd,composite-clock";
			#clock-cells = <0x0>;
			reg = <0x402d02f4 0x4>;
			sprd,mux-msk = <0x3>;
			sprd,div-msk = <0x300>;
			clocks = <0x3 0x86 0x20>;
			clock-output-names = "clk_io_apb";
		};

		clk@402d02f8 {
			compatible = "sprd,gates-clock";
			#clock-cells = <0x1>;
			reg = <0x402d02f8 0x4>;
			sprd,gates-msk = <0x10000>;
			clocks = <0x8b>;
			clock-output-names = "clk_dtck_hw";
		};

		clk@60100004 {
			compatible = "sprd,composite-clock";
			#clock-cells = <0x0>;
			reg = <0x60100004 0x4>;
			sprd,mux-msk = <0x7>;
			sprd,div-msk = <0x30>;
			clocks = <0x3b 0x5d 0x5e 0x5f 0x33 0xe 0x49>;
			clock-output-names = "clk_gpu";
			linux,phandle = <0x5c>;
			phandle = <0x5c>;
		};

		clk@60d00000 {
			compatible = "sprd,sc1000-gates-clock";
			#clock-cells = <0x1>;
			reg = <0x60d00000 0x3000>;
			sprd,gates-msk = <0x7f>;
			clocks = <0x64>;
			clock-output-names = "dcam_eb", "isp_eb", "vsp_eb", "csi_eb", "jpg_eb", "mm_ckg_eb", "vsp_mq_ahb_eb";
			linux,phandle = <0x63>;
			phandle = <0x63>;
		};

		clk@60d00008 {
			compatible = "sprd,gates-clock";
			#clock-cells = <0x1>;
			reg = <0x60d00008 0x4>;
			sprd,gates-msk = <0x1f>;
			clocks = <0x64>;
			clock-output-names = "mcphy_cfg_eb", "msensor0_en", "misp_axi_en", "mdcam_axi_en", "mmipi_csi_en";
			linux,phandle = <0x1d>;
			phandle = <0x1d>;
		};

		clk@60e00020 {
			compatible = "sprd,muxed-clock";
			#clock-cells = <0x0>;
			reg = <0x60e00020 0x4>;
			sprd,mux-msk = <0x7>;
			clocks = <0x3 0x1e 0x6b 0x3b 0x94>;
			clock-output-names = "clk_mm_ahb";
			linux,phandle = <0x64>;
			phandle = <0x64>;
		};

		clk@60e00024 {
			compatible = "sprd,composite-clock";
			#clock-cells = <0x0>;
			reg = <0x60e00024 0x4>;
			sprd,mux-msk = <0x3>;
			sprd,div-msk = <0x700>;
			clocks = <0x3 0x20 0x1f 0x1e>;
			clock-output-names = "clk_sensor0";
			linux,phandle = <0x1c>;
			phandle = <0x1c>;
		};

		clk@60e00028 {
			compatible = "sprd,muxed-clock";
			#clock-cells = <0x0>;
			reg = <0x60e00028 0x4>;
			sprd,mux-msk = <0x3>;
			clocks = <0x6b 0x5e 0x5f 0x7f>;
			clock-output-names = "clk_dcam";
			linux,phandle = <0x65>;
			phandle = <0x65>;
		};

		clk@60e0002c {
			compatible = "sprd,muxed-clock";
			#clock-cells = <0x0>;
			reg = <0x60e0002c 0x4>;
			sprd,mux-msk = <0x3>;
			clocks = <0x6b 0x5e 0x5f 0x7f>;
			clock-output-names = "clk_vsp";
			linux,phandle = <0x68>;
			phandle = <0x68>;
		};

		clk@60e00030 {
			compatible = "sprd,muxed-clock";
			#clock-cells = <0x0>;
			reg = <0x60e00030 0x4>;
			sprd,mux-msk = <0x3>;
			clocks = <0x6b 0x5e 0x5f 0x7f>;
			clock-output-names = "clk_isp";
			linux,phandle = <0x6a>;
			phandle = <0x6a>;
		};

		clk@60e00034 {
			compatible = "sprd,muxed-clock";
			#clock-cells = <0x0>;
			reg = <0x60e00034 0x4>;
			sprd,mux-msk = <0x3>;
			clocks = <0x1f 0x6b 0x5e 0x7b>;
			clock-output-names = "clk_jpg";
			linux,phandle = <0x6e>;
			phandle = <0x6e>;
		};

		clk@60e00038 {
			compatible = "sprd,gates-clock";
			#clock-cells = <0x1>;
			reg = <0x60e00038 0x4>;
			sprd,gates-msk = <0x10000>;
			clocks = <0x64>;
			clock-output-names = "clk_mipi_csi";
			linux,phandle = <0x6f>;
			phandle = <0x6f>;
		};

		clk@60e00040 {
			compatible = "sprd,muxed-clock";
			#clock-cells = <0x0>;
			reg = <0x60e00040 0x4>;
			sprd,mux-msk = <0x3>;
			clocks = <0x5f 0x7f 0xe 0x95>;
			clock-output-names = "clk_dcam_axi";
			linux,phandle = <0x66>;
			phandle = <0x66>;
		};

		clk@60e00044 {
			compatible = "sprd,muxed-clock";
			#clock-cells = <0x0>;
			reg = <0x60e00044 0x4>;
			sprd,mux-msk = <0x3>;
			clocks = <0x5f 0x7f 0xe 0x95>;
			clock-output-names = "clk_isp_axi";
			linux,phandle = <0x6c>;
			phandle = <0x6c>;
		};

		clk@20e00000 {
			compatible = "sprd,sc1000-gates-clock";
			#clock-cells = <0x1>;
			sprd,gates-msk = <0x58001d7b>;
			reg = <0x20e00000 0x3000>;
			clocks = <0x96>;
			clock-output-names = "dsi_eb", "dispc_eb", "gsp_eb", "otg_eb", "ree_dma_eb", "ce_pub_eb", "sdio0_eb", "nandc_eb", "emmc_eb", "ce_sec_eb", "emmc_32k_eb", "sdio0_32k_eb", "nandc_ecc_eb";
			linux,phandle = <0x2f>;
			phandle = <0x2f>;
		};

		clk@71300000 {
			compatible = "sprd,sc1000-gates-clock";
			#clock-cells = <0x1>;
			sprd,gates-msk = <0x7a6723>;
			reg = <0x71300000 0x3000>;
			clocks = <0x97>;
			clock-output-names = "sim0_eb", "iis0_eb", "spi0_eb", "i2c0_eb", "i2c1_eb", "i2c2_eb", "uart0_eb", "uart1_eb", "sim0_32k_eb", "intc0_eb", "intc1_eb", "intc2_eb", "intc3_eb";
			linux,phandle = <0x19>;
			phandle = <0x19>;
		};

		clk@402e0000 {
			compatible = "sprd,sc1000-gates-clock";
			#clock-cells = <0x1>;
			sprd,gates-msk = <0xff5ffff8>;
			reg = <0x402e0000 0x3000>;
			clocks = <0x8b>;
			clock-output-names = "gpio_eb", "pwm0_eb", "pwm1_eb", "pwm2_eb", "pwm3_eb", "kpd_eb", "aon_syst_eb", "ap_syst_eb", "aon_tmr_eb", "ap_tmr0_eb", "ree_efuse_eb", "eic_eb", "intc_eb", "adi_eb", "audif_eb", "aud_eb", "vbc_eb", "pin_eb", "splk_eb", "ap_wdg_eb", "mm_eb", "aon_ckg_eb", "gpu_eb", "ca7_ts0_eb", "ca7_ts1_eb", "ca7_dap_eb", "i2c_eb";
			linux,phandle = <0x44>;
			phandle = <0x44>;
		};

		clk@402e0004 {
			compatible = "sprd,sc1000-gates-clock";
			#clock-cells = <0x1>;
			sprd,gates-msk = <0xf3f66fff>;
			reg = <0x402e0004 0x3000>;
			clocks = <0x8b>;
			clock-output-names = "pmu_eb", "thm_eb", "aux0_eb", "aux1_eb", "aux2_eb", "probe_eb", "avs_eb", "clk_emc_ref_eb", "ca7_wdg_eb", "ap_tmr1_eb", "ap_tmr2_eb", "djtag_apb_eb", "gsp_emc_eb", "mm_vsp_eb", "mdar_eb", "rtc4m0_cal_eb", "djtag_eb", "mbox_eb", "ree_aon_dma_eb", "cm4_djtag_eb", "wcn_eb", "def_eb", "dbg_eb", "dbg_emc_eb", "cross_trig_eb", "serdes_dphy_eb";
			linux,phandle = <0x45>;
			phandle = <0x45>;
		};

		clk@402e0010 {
			compatible = "sprd,sc1000-gates-clock";
			#clock-cells = <0x1>;
			sprd,gates-msk = <0x7ffff>;
			reg = <0x402e0010 0x3000>;
			clocks = <0x8b>;
			clock-output-names = "arch_rtc_eb", "kpd_rtc_eb", "aon_syst_rtc_eb", "ap_syst_rtc_eb", "aon_tmr_rtc_eb", "ap_tmr0_rtc_eb", "eic_rtc_eb", "eic_rtcdiv5_eb", "ap_wdg_rtc_eb", "ca7_wdg_rtc_eb", "thm_rtc_eb", "arm_ta_rtc_eb", "gpu_ta_rtc_eb", "arm_ta_rtc_aen", "gpu_ta_rtc_aen", "ap_tmr1_rtc_eb", "ap_tmr2_rtc_eb", "dcxo_lc_rtc_eb", "bb_cal_rtc_eb";
			linux,phandle = <0x4b>;
			phandle = <0x4b>;
		};

		clk@402e00b0 {
			compatible = "sprd,sc1000-gates-clock";
			#clock-cells = <0x1>;
			sprd,gates-msk = <0xfff0>;
			reg = <0x402e00b0 0x3000>;
			clocks = <0x8b>;
			clock-output-names = "cssys_eb", "dmc_eb", "pub_reg_eb", "rosc_eb", "sdphy_cfg_eb", "sdphy_ref_eb", "busmon_dma_eb", "anlg_eb", "pin_apb_eb", "anlg_apb_eb", "bsmtmr_eb", "ap_dap_eb";
		};

		clk@402e0134 {
			compatible = "sprd,sc1000-gates-clock";
			#clock-cells = <0x1>;
			sprd,gates-msk = <0x40fff>;
			reg = <0x402e0134 0x3000>;
			clocks = <0x8b>;
			clock-output-names = "emmc_1x_eb", "emmc_2x_eb", "sdio0_1x_eb", "sdio0_2x_eb", "sdio1_1x_eb", "sdio1_2x_eb", "nandc_1x_eb", "nandc_2x_eb", "cssys_ca7_eb", "ap_hs_spi_eb", "det_32k_eb", "tmr_eb", "apll_test_eb";
			linux,phandle = <0x2c>;
			phandle = <0x2c>;
		};
	};

	sprd-pcm-audio {
		compatible = "sprd,pcm-platform-sharkl2";
		#sound-dai-cells = <0x0>;
		dmas = <0x17 0x1 0x17 0x2 0x17 0x3 0x17 0x4 0x17 0x5 0x17 0x6 0x17 0x7 0x17 0x8 0x29 0x1 0x29 0x2 0x29 0x3 0x29 0x4>;
		dma-names = "da01-l", "da01-r", "da23-l", "da23-r", "normal-2stage-p", "normal-2stage-c", "deep-2stage-p", "ad23-2stage-c", "ad01-l", "ad01-r", "ad23-l", "ad23-r";
		sprd,dma-2stage-usecase = <0x2>;
		sprd,node-count-2stage-level-1 = <0x1>;
		sprd,syscon-pmu-apb = <0x4d>;
		sprd,dma-2stage-level-1-int-source = <0x1>;
		linux,phandle = <0xa7>;
		phandle = <0xa7>;
	};

	sprd-pcm-iis {
		compatible = "sprd,pcm-platform-sharkl2";
		#sound-dai-cells = <0x0>;
		dmas = <0x29 0x5 0x29 0x6 0x29 0x7 0x29 0x8 0x29 0x9 0x29 0xa 0x29 0xb 0x29 0xc>;
		dma-names = "iis0_tx", "iis0_rx", "iis1_tx", "iis1_rx", "iis2_tx", "iis2_rx", "iis3_tx", "iis3_rx";
		sprd,dma-2stage-usecase = <0x2>;
		sprd,node-count-2stage-level-1 = <0x1>;
		sprd,syscon-pmu-apb = <0x4d>;
		sprd,dma-2stage-level-1-int-source = <0x1>;
		linux,phandle = <0xab>;
		phandle = <0xab>;
	};

	vaudio {
		compatible = "sprd,vaudio";
		#sound-dai-cells = <0x1>;
		linux,phandle = <0xaa>;
		phandle = <0xaa>;
	};

	saudio_lte {
		compatible = "sprd,saudio";
		sprd,saudio-dst-id = <0x5>;
		sprd,ctrl_channel = <0xa>;
		sprd,playback_channel = <0xb 0x83>;
		sprd,capture_channel = <0xc>;
		sprd,monitor_channel = <0xd>;
		sprd,device = <0x2>;
		sprd,saudio-names = "saudiolte";
	};

	saudio_voip {
		compatible = "sprd,saudio";
		sprd,saudio-dst-id = <0x5>;
		sprd,ctrl_channel = <0xe>;
		sprd,playback_channel = <0xf 0x97>;
		sprd,capture_channel = <0x10>;
		sprd,monitor_channel = <0x11>;
		sprd,device = <0x2>;
		sprd,saudio-names = "saudiovoip";
	};

	audio-mem-mgr {
		compatible = "sprd,audio-mem-sharkl2";
		sprd,iram_phy_addr = <0x50000000 0xb000>;
		sprd,iram_normal = <0x50000000 0x0>;
		sprd,iram_deepbuf = <0x50000000 0xa000>;
		sprd,iram_4arm7 = <0x5000a000 0x1000>;
	};

	sleep-ctrl {
		compatible = "sprd,sleep-ctrl";
		sprd,sys-aon-apb = <0x16>;
		sprd,aon_reg = <0x530>;
	};

	clk-default {
		compatible = "sprd,clk-default";
		sprd,syscon-pmu-apb = <0x4d>;
		sprd,syscon-aon-apb = <0x16>;
		pmu-pwd-list = <0x1c 0x3000000 0x2000000 0x20 0x3000000 0x2000000>;
		clock-names = "clk_gpu_eb", "clk_cam_eb";
		clocks = <0x44 0x1b 0x44 0x19>;
	};

	mailbox@400a0000 {
		compatible = "sprd,mailbox";
		reg = <0x400a0000 0x8000 0x400a8000 0x8000>;
		sprd,syscon-ap-apb = <0x16>;
		interrupts = <0x0 0x44 0x4 0x0 0x45 0x4>;
		sprd,core-cnt = <0x6>;
		sprd,version = <0x3>;
	};

	scproc@50800000 {
		compatible = "sprd,scproc_pubcp";
		sprd,name = "pmic";
		sprd,syscon-ap-apb = <0x16>;
		sprd,syscon-ap-pmu = <0x4d>;
		sprd,ctrl-reg = <0xff 0xff 0x114 0xff 0xff>;
		sprd,ctrl-mask = <0x0 0x200000 0x1 0x0 0x0>;
		sprd,ctrl-type = <0x0 0x1 0x0 0x0 0x0>;
		reg = <0x50800000 0x10000>;
		#address-cells = <0x1>;
		#size-cells = <0x1>;
		ranges = <0x0 0x50800000 0x10000>;

		pm_sys@0 {
			cproc,name = "pm_sys";
			reg = <0x0 0x10000>;
		};
	};

	sipc@5000b000 {
		compatible = "sprd,sipc-v1";
		sprd,name = "sipc-pmsys";
		sprd,dst = <0x6 0x1>;
		sprd,smem-info = <0x5000b000 0x2000b000 0x800>;
	};

	scproc@5000d000 {
		compatible = "sprd,scproc_pubcp";
		sprd,decoup = "cproc-use-decoup";
		sprd,name = "cptl";
		sprd,syscon-ap-apb = <0x16>;
		sprd,syscon-ap-pmu = <0x4d>;
		sprd,ctrl-reg = <0x48 0xcc 0x284 0xb0 0xff>;
		sprd,ctrl-mask = <0x2000000 0x40000 0x400 0x2 0x0>;
		sprd,ctrl-type = <0x1 0x1 0x0 0x1 0x0>;
		reg = <0x5000d000 0x1000>;
		interrupts = <0x0 0x53 0x0>;
		#address-cells = <0x1>;
		#size-cells = <0x1>;
	};

	sipc@87800000 {
		compatible = "sprd,sipc-v1";
		sprd,name = "sipc-lte";
		sprd,dst = <0x5 0x2>;
		sprd,smem-info = <0x87800000 0x87800000 0x200000>;
	};

	spipe-pm-log {
		compatible = "sprd,spipe";
		sprd,name = "slog_pm";
		sprd,dst = <0x6>;
		sprd,channel = <0x5>;
		sprd,ringnr = <0x1>;
		sprd,size-rxbuf = <0x5b0>;
		sprd,size-txbuf = <0x100>;
	};

	spipe-pm-ctl {
		compatible = "sprd,spipe";
		sprd,name = "sctl_pm";
		sprd,dst = <0x6>;
		sprd,channel = <0x6>;
		sprd,ringnr = <0x1>;
		sprd,size-rxbuf = <0xc0>;
		sprd,size-txbuf = <0x40>;
	};

	spipe@4 {
		compatible = "sprd,spipe";
		sprd,name = "spipe_lte";
		sprd,dst = <0x5>;
		sprd,channel = <0x4>;
		sprd,ringnr = <0xf>;
		sprd,size-rxbuf = <0x1000>;
		sprd,size-txbuf = <0x1000>;
	};

	spool@5 {
		compatible = "sprd,spool";
		sprd,name = "slog_lte";
		sprd,dst = <0x5>;
		sprd,channel = <0x5>;
		sprd,tx-blksize = <0x0>;
		sprd,tx-blknum = <0x0>;
		sprd,rx-blksize = <0x10000>;
		sprd,rx-blknum = <0x4>;
	};

	spipe@21 {
		compatible = "sprd,spipe";
		sprd,name = "sdiag_lte";
		sprd,dst = <0x5>;
		sprd,channel = <0x15>;
		sprd,ringnr = <0x1>;
		sprd,size-rxbuf = <0x40000>;
		sprd,size-txbuf = <0x8000>;
	};

	stty@6 {
		compatible = "sprd,spipe";
		sprd,name = "stty_lte";
		sprd,dst = <0x5>;
		sprd,channel = <0x6>;
		sprd,ringnr = <0x20>;
		sprd,size-rxbuf = <0x800>;
		sprd,size-txbuf = <0x800>;
	};

	sipx-lte {
		compatible = "sprd,sipx";
		sprd,name = "sipx_lte";
		sprd,dst = <0x5>;
		sprd,dl-pool = <0x80>;
		sprd,dl-ack-pool = <0x0>;
		sprd,ul-pool = <0x100>;
		sprd,ul-ack-pool = <0x100>;
	};

	seth@7 {
		compatible = "sprd,seth";
		sprd,name = "seth_lte0";
		sprd,dst = <0x5>;
		sprd,channel = <0x7>;
		sprd,blknum = <0x100>;
		sprd,poolsize = <0x10>;
	};

	seth@8 {
		compatible = "sprd,seth";
		sprd,name = "seth_lte1";
		sprd,dst = <0x5>;
		sprd,channel = <0x8>;
		sprd,blknum = <0x100>;
		sprd,poolsize = <0x10>;
	};

	seth@9 {
		compatible = "sprd,seth";
		sprd,name = "seth_lte2";
		sprd,dst = <0x5>;
		sprd,channel = <0x9>;
		sprd,blknum = <0x100>;
		sprd,poolsize = <0x10>;
	};

	seth@18 {
		compatible = "sprd,seth";
		sprd,name = "seth_lte3";
		sprd,dst = <0x5>;
		sprd,channel = <0x12>;
		sprd,blknum = <0x100>;
		sprd,poolsize = <0x10>;
	};

	seth@19 {
		compatible = "sprd,seth";
		sprd,name = "seth_lte4";
		sprd,dst = <0x5>;
		sprd,channel = <0x13>;
		sprd,blknum = <0x100>;
		sprd,poolsize = <0x10>;
	};

	seth@20 {
		compatible = "sprd,seth";
		sprd,name = "seth_lte5";
		sprd,dst = <0x5>;
		sprd,channel = <0x14>;
		sprd,blknum = <0x100>;
		sprd,poolsize = <0x10>;
	};

	cpus {
		#address-cells = <0x1>;
		#size-cells = <0x0>;

		cpu-map {

			cluster0 {

				core0 {
					cpu = <0xc>;
				};

				core1 {
					cpu = <0x10>;
				};

				core2 {
					cpu = <0x12>;
				};

				core3 {
					cpu = <0x14>;
				};
			};
		};

		cpu@0 {
			device_type = "cpu";
			compatible = "arm,cortex-a7";
			enable-method = "psci";
			reg = <0x0>;
			cpufreq-data-v1 = <0x98>;
			cpu-idle-states = <0x99>;
			cpu-supply = <0x5a>;
			linux,phandle = <0xc>;
			phandle = <0xc>;
		};

		cpu@1 {
			device_type = "cpu";
			compatible = "arm,cortex-a7";
			enable-method = "psci";
			reg = <0x1>;
			cpufreq-data-v1 = <0x98>;
			cpu-idle-states = <0x99>;
			cpu-supply = <0x5a>;
			linux,phandle = <0x10>;
			phandle = <0x10>;
		};

		cpu@2 {
			device_type = "cpu";
			compatible = "arm,cortex-a7";
			enable-method = "psci";
			reg = <0x2>;
			cpufreq-data-v1 = <0x98>;
			cpu-idle-states = <0x99>;
			cpu-supply = <0x5a>;
			linux,phandle = <0x12>;
			phandle = <0x12>;
		};

		cpu@3 {
			device_type = "cpu";
			compatible = "arm,cortex-a7";
			enable-method = "psci";
			reg = <0x3>;
			cpufreq-data-v1 = <0x98>;
			cpu-idle-states = <0x99>;
			cpu-supply = <0x5a>;
			linux,phandle = <0x14>;
			phandle = <0x14>;
		};
	};

	cpufreq-clus0 {
		clocks = <0x7a 0x78 0x79>;
		clock-names = "core_clk", "low_freq_clk_parent", "high_freq_clk_parent";
		clock-latency = <0xc350>;
		cpu-gpu-vdd = <0x1>;
		sprd,syscon-aon-apb = <0x16>;
		voltage-tolerance = <0x0>;
		default-efuse-blk-binning = <0x1>;
		sprd,efuse-blk-binning = <0x2b 0xf00>;
		sprd,cpufreq-temp-threshold = <0x32>;
		operating-points-0-0 = <0x13d620 0xf97b3 0x124f80 0xf1da1 0x118c30 0xee098 0x10c8e0 0xeafc4 0xf4240 0xe35b2 0xdbba0 0xdbba0 0xbb800 0xdbba0>;
		operating-points-1-0 = <0x13d620 0xe7ef0 0x124f80 0xe1d48 0x118c30 0xdec74 0x10c8e0 0xdbba0 0xf4240 0xdbba0 0xdbba0 0xdbba0 0xbb800 0xdbba0>;
		operating-points-2-0 = <0x13d620 0xf1da1 0x124f80 0xeafc4 0x118c30 0xe72bb 0x10c8e0 0xe35b2 0xf4240 0xdbba0 0xdbba0 0xdbba0 0xbb800 0xdbba0>;
		operating-points-3-0 = <0x13d620 0xf97b3 0x124f80 0xf1da1 0x118c30 0xee098 0x10c8e0 0xeafc4 0xf4240 0xe35b2 0xdbba0 0xdbba0 0xbb800 0xdbba0>;
		operating-points-4-0 = <0x13d620 0x100590 0x124f80 0xf97b3 0x118c30 0xf5aaa 0x10c8e0 0xf1da1 0xf4240 0xeafc4 0xdbba0 0xe35b2 0xbb800 0xdbba0>;
		operating-points-0-0-50 = <0x13d620 0xfe0f1 0x124f80 0xf5aaa 0x118c30 0xf116c 0x10c8e0 0xed463 0xf4240 0xe4e1c 0xdbba0 0xdbba0 0xbb800 0xdbba0>;
		operating-points-1-0-50 = <0x13d620 0xed463 0x124f80 0xe4e1c 0x118c30 0xe04de 0x10c8e0 0xdbba0 0xf4240 0xdbba0 0xdbba0 0xdbba0 0xbb800 0xdbba0>;
		operating-points-2-0-50 = <0x13d620 0xf7314 0x124f80 0xee098 0x118c30 0xe975a 0x10c8e0 0xe4e1c 0xf4240 0xdbba0 0xdbba0 0xdbba0 0xbb800 0xdbba0>;
		operating-points-3-0-50 = <0x13d620 0xfe0f1 0x124f80 0xf5aaa 0x118c30 0xf116c 0x10c8e0 0xed463 0xf4240 0xe4e1c 0xdbba0 0xdbba0 0xbb800 0xdbba0>;
		operating-points-4-0-50 = <0x124f80 0xfd4bc 0x118c30 0xf97b3 0x10c8e0 0xf4e75 0xf4240 0xec82e 0xdbba0 0xe41e7 0xbb800 0xdbba0>;
		linux,phandle = <0x98>;
		phandle = <0x98>;
	};

	idle-states {
		sprd,sys-ap-ahb = <0x2e>;
		sprd,sys-ap-apb = <0x2d>;
		sprd,sys-aon-apb = <0x16>;
		sprd,sys-pmu-apb = <0x4d>;
		sprd,sys-ap-intc0 = <0x9a>;
		sprd,sys-ap-intc1 = <0x9b>;
		sprd,sys-ap-intc2 = <0x9c>;
		sprd,sys-ap-intc3 = <0x9d>;

		light_sleep {
			compatible = "arm,idle-state";
			entry-latency-us = <0x14>;
			exit-latency-us = <0xa>;
			min-residency-us = <0x32>;
			local-timer-stop;
			linux,phandle = <0x99>;
			phandle = <0x99>;
		};

		heavy_sleep {
			compatible = "arm,idle-state";
			entry-latency-us = <0x190>;
			exit-latency-us = <0x2bc>;
			min-residency-us = <0x4b0>;
			local-timer-stop;
		};
	};

	psci {
		compatible = "arm,psci-1.0";
		method = "smc";
	};

	interrupt-controller@12001000 {
		compatible = "arm,cortex-a15-gic", "arm,cortex-a9-gic";
		#interrupt-cells = <0x3>;
		#address-cells = <0x0>;
		interrupt-controller;
		reg = <0x12001000 0x1000 0x12002000 0x1000>;
		linux,phandle = <0x1>;
		phandle = <0x1>;
	};

	timer {
		compatible = "arm,armv7-timer";
		interrupts = <0x1 0xe 0xf08 0x1 0xa 0xf08>;
		clock-frequency = <0x18cba80>;
	};

	pmu {
		compatible = "arm,cortex-a7-pmu";
		interrupts = <0x0 0x5c 0x4 0x0 0x5d 0x4 0x0 0x5e 0x4 0x0 0x5f 0x4>;
	};

	sprd-gsp {
		compatible = "sprd,gsp-lite_r2p0-pike2";
		core-cnt = <0x1>;
		io-cnt = <0x7>;
		cores = <0x9e>;
	};

	deep-sleep {
		sprd,sys-base = <0x2d 0x2e 0x4d 0x16>;
		sprd,sys-intc = <0x9a 0x9b 0x9c 0x9d 0x9f>;
		clocks = <0x3 0x7a 0xa0 0xa1 0x96 0x80 0x97 0x39 0x3c 0x3d 0x18 0x1a 0x1b 0x27 0x28 0x2a 0xa2 0xa3 0xa4>;
	};

	lcds {

		lcd7701@7701 {
			work-mode = <0x1>;
			bpp = <0x18>;
			lane-number = <0x2>;
			need-check-esd = <0x1>;
			esd-timeout = <0x3e8>;
			esd-check-reg = <0xa>;
			esd-return-code = <0x9c>;
			fps = <0x3c>;
			width-mm = <0x44>;
			height-mm = <0x79>;
			panel-name = "lcd_st7701_2lane_mipi_y400_ykl_fwvga";
			power-on-sequence = <0x20 0x1 0xa 0x20 0x0 0xa 0x20 0x1 0x78>;
			power-off-sequence = <0x20 0x0 0x14>;
			init-data = <0x23780002 0x11003900 0x6ff77 0x1000010 0x39000003 0xc0f70139 0x3c1 0xe023900 0x3c207 0x2230000 0x2cc3839 0x11b0 0x30b0e 0x160c0c09 0x91f0915 0x118f12d4 0x39000011 0xb1000309 0x10160908 0xa092208 0x1715961b 0xd4390000 0x6ff7701 0x1123 0x2b0 0x4d230000 0x2b15823 0x2b2 0x87230000 0x2b38023 0x2b5 0x4e230000 0x2b78723 0x2b8 0x20230000 0x2c00023 0x2c1 0x78230000 0x2c27823 0x2d0 0x88390000 0x4e00000 0x2390000 0xce1078c 0x98c068c 0x88c0044 0x44390000 0xee20000 0x0 0x0 0x39 0x5e3 0x3333 0x39000003 0xe4444439 0x11e5 0xfca8c8c 0x11ca8c8c 0xbca8c8c 0xdca8c8c 0x39000005 0xe6000033 0x33390000 0x3e74444 0x39000011 0xe80eca8c 0x8c10ca8c 0x8c0aca8c 0x8c0cca8c 0x8c390000 0x8eb0200 0x0 0x390000 0x11edab89 0x765401ff 0xffffffff 0xff104567 0x98ba3900 0x6ff77 0x1000000 0x23000002 0x3500230a 0x22900>;
			sleep-in = [13 0a 00 01 28 13 78 00 01 10];
			sleep-out = [13 78 00 01 11 13 0a 00 01 29];
			linux,phandle = <0xb9>;
			phandle = <0xb9>;

			display-timings {
				clock-frequency = <0x7a120>;
				hactive = <0x1e0>;
				vactive = <0x3c0>;
				hback-porch = <0x50>;
				hfront-porch = <0x50>;
				vback-porch = <0x10>;
				vfront-porch = <0x12>;
				hsync-len = <0x14>;
				vsync-len = <0x2>;
			};
		};

		lcd9503@9503 {
			work-mode = <0x1>;
			bpp = <0x18>;
			lane-number = <0x2>;
			need-check-esd = <0x1>;
			esd-timeout = <0x3e8>;
			fps = <0x3c>;
			width-mm = <0x38>;
			height-mm = <0x70>;
			panel-name = "lcd_gc9503_2lane_mipi_y400_hifay_fwvga";
			power-on-sequence = <0x20 0x1 0x5 0x20 0x0 0x5 0x20 0x1 0x14>;
			power-off-sequence = <0x20 0x0 0x14>;
			init-data = <0x39000006 0xf055aa52 0x8003900 0x3f65a 0x87230000 0x2c13f23 0x2c2 0x8f230000 0x2c6f823 0x2cd 0x25230000 0x2c8c123 0x2c9 0x10230000 0x26c0023 0x2f8 0x8a230000 0x2ac6523 0x2a7 0x77230000 0x2a65723 0x2a0 0xdd230000 0x2700139 0x377 0x83900 0x48704 0x3663900 0x4fa8f 0x2300 0x297dd 0x23000002 0x83932300 0x2a322 0x39000004 0xfd283c00 0x39000005 0x8699a3a3 0x51230000 0x2b11039 0x37a 0x131a3900 0x37b13 0x1a230000 0x26ba739 0x960 0x280a1a7a 0x28001073 0x39000009 0x63280068 0x6828091a 0x7a390000 0x216d1d1d 0x1d1d1d1e 0x1e1e191e 0x1a1e1e1e 0x1e1e1e1e 0x1e1e1e1c 0x1e1b1e1e 0x1e1d1d1d 0x1d1d3900 0x116418 0x803c300 0x3180703 0xc400031a 0x7a1a7a39 0x1165 0x180603c5 0x31805 0x3c60003 0x1a7a1a7a 0x39000011 0x66180403 0xc7000318 0x303c800 0x31a7a1a 0x7a390000 0x11671802 0x3c90003 0x180103ca 0x31a7a 0x1a7a3900 0xe6803 0x80c080b 0x80e 0x80d0000 0x39000008 0x69144814 0x48144810 0x39000009 0x6a081848 0xb012345 0x67230000 0x26ba739 0x35d1 0x0 0x90015 0x200038 0x4a0118 0x17701e5 0x2250270 0x2a502a6 0x2d60305 0x3240344 0x3570370 0x3830396 0x3a403ad 0x3bd03ff 0x39000035 0xd2000000 0x900 0x15002000 0x38004a01 0x18017701 0xe5022502 0x7002a502 0xa602d603 0x5032403 0x44035703 0x70038303 0x9603a403 0xad03bd03 0xff390000 0x35d30000 0x9 0x150020 0x38004a 0x1180177 0x1e50225 0x27002a5 0x2a602d6 0x3050324 0x3440357 0x3700383 0x39603a4 0x3ad03bd 0x3ff3900 0x35d400 0x0 0x9001500 0x20003800 0x4a011801 0x7701e502 0x25027002 0xa502a602 0xd6030503 0x24034403 0x57037003 0x83039603 0xa403ad03 0xbd03ff39 0x35d5 0x0 0x90015 0x200038 0x4a0118 0x17701e5 0x2250270 0x2a502a6 0x2d60305 0x3240344 0x3570370 0x3830396 0x3a403ad 0x3bd03ff 0x39000035 0xd6000000 0x900 0x15002000 0x38004a01 0x18017701 0xe5022502 0x7002a502 0xa602d603 0x5032403 0x44035703 0x70038303 0x9603a403 0xad03bd03 0xff237800 0x2110039 0x216d 0x8100e0c 0xa1e1e1e 0x191e1a1e 0x1e1e1e1e 0x1e1e1e1e 0x1e1c1e1b 0x1e1e1e09 0xb0d0f01 0x39000003 0x77000023 0x2a6 0x56390000 0x58699a3 0xa351230a 0x22900>;
			sleep-in = [13 0a 00 01 28 13 78 00 01 10];
			sleep-out = [13 78 00 01 11 13 64 00 01 29];
			linux,phandle = <0xba>;
			phandle = <0xba>;

			display-timings {
				clock-frequency = <0x7a120>;
				hactive = <0x1e0>;
				vactive = <0x3c0>;
				hback-porch = <0x3c>;
				hfront-porch = <0x32>;
				vback-porch = <0x14>;
				vfront-porch = <0x14>;
				hsync-len = <0x8>;
				vsync-len = <0x8>;
			};
		};

		lcd66@66 {
			work-mode = <0x1>;
			bpp = <0x18>;
			lane-number = <0x2>;
			need-check-esd = <0x1>;
			esd-timeout = <0x3e8>;
			esd-check-reg = <0xa>;
			esd-return-code = <0x9c>;
			fps = <0x3c>;
			width-mm = <0x38>;
			height-mm = <0x70>;
			panel-name = "lcd_gc9503_2lane_mipi_y400_hifay_fwvga_ivo";
			power-on-sequence = <0x20 0x1 0xa 0x20 0x0 0xa 0x20 0x1 0x78>;
			power-off-sequence = <0x20 0x1 0x14>;
			init-data = [39 00 00 06 f0 55 aa 52 08 00 39 00 00 03 f6 5a 87 23 00 00 02 c1 3f 23 00 00 02 c2 0e 23 00 00 02 c6 f8 23 00 00 02 c9 10 23 00 00 02 cd 25 23 00 00 02 f8 8a 23 00 00 02 ac 65 39 00 00 04 fa 8f 00 00 23 00 00 02 a3 22 39 00 00 04 fd 28 3c 00 23 00 00 02 a7 47 23 00 00 02 a0 ee 23 00 00 02 b1 10 39 00 00 03 7a 0f 13 39 00 00 03 7b 0f 13 39 00 00 21 6d 1e 1e 1e 03 01 09 0f 0b 0d 05 07 1e 1e 1e 1e 1e 1e 1e 1e 1e 1e 08 06 0e 0c 10 0a 02 04 1e 1e 1e 39 00 00 09 60 38 09 7a 7a 38 08 7a 7a 39 00 00 09 61 38 07 7a 7a 38 06 7a 7a 39 00 00 09 62 33 bb 7a 7a 33 bc 7a 7a 39 00 00 09 63 33 bd 7a 7a 33 be 7a 7a 39 00 00 11 64 28 06 03 c2 03 03 28 05 03 c3 03 03 7a 7a 7a 7a 39 00 00 11 65 28 02 03 c6 03 03 28 01 03 c7 03 03 7a 7a 7a 7a 39 00 00 11 66 20 00 03 c8 03 03 20 01 03 c9 03 03 7a 7a 7a 7a 39 00 00 11 67 28 04 03 c4 03 03 28 03 03 c5 03 03 7a 7a 7a 7a 39 00 00 08 69 14 22 14 22 44 22 08 23 00 00 02 6b 07 39 00 00 35 d1 00 00 00 04 00 29 00 52 00 80 00 cb 00 f8 01 48 01 78 01 bb 01 ee 02 30 02 62 02 64 02 92 02 c2 02 da 02 fa 03 0b 03 24 03 32 03 48 03 50 03 68 03 78 03 ff 39 00 00 35 d2 00 00 00 04 00 29 00 52 00 80 00 cb 00 f8 01 48 01 78 01 bb 01 ee 02 30 02 62 02 64 02 92 02 c2 02 da 02 fa 03 0b 03 24 03 32 03 48 03 50 03 68 03 78 03 ff 39 00 00 35 d3 00 00 00 04 00 29 00 52 00 80 00 cb 00 f8 01 48 01 78 01 bb 01 ee 02 30 02 62 02 64 02 92 02 c2 02 da 02 fa 03 0b 03 24 03 32 03 48 03 50 03 68 03 78 03 ff 39 00 00 35 d4 00 00 00 04 00 29 00 52 00 80 00 cb 00 f8 01 48 01 78 01 bb 01 ee 02 30 02 62 02 64 02 92 02 c2 02 da 02 fa 03 0b 03 24 03 32 03 48 03 50 03 68 03 78 03 ff 39 00 00 35 d5 00 00 00 04 00 29 00 52 00 80 00 cb 00 f8 01 48 01 78 01 bb 01 ee 02 30 02 62 02 64 02 92 02 c2 02 da 02 fa 03 0b 03 24 03 32 03 48 03 50 03 68 03 78 03 ff 39 00 00 35 d6 00 00 00 04 00 29 00 52 00 80 00 cb 00 f8 01 48 01 78 01 bb 01 ee 02 30 02 62 02 64 02 92 02 c2 02 da 02 fa 03 0b 03 24 03 32 03 48 03 50 03 68 03 78 03 ff 23 78 00 02 11 00 23 0a 00 02 29 00];
			sleep-in = [23 14 00 02 6c 60 23 00 00 02 b1 00 39 14 00 05 fa 7f 00 00 00 23 0a 00 02 6c 50 23 32 00 02 28 00 23 14 00 02 10 00 39 00 00 06 f0 55 aa 52 08 00 23 00 00 02 c2 ce 23 00 00 02 c3 cd 23 00 00 02 c6 fc 23 00 00 02 c5 03 23 00 00 02 cd 64 23 00 00 02 c4 ff 23 00 00 02 c9 cd 39 00 00 03 f6 5a 87 39 00 00 04 fd aa aa 0a 39 00 00 03 fe 6a 0a 39 00 00 03 78 2a aa 39 00 00 03 92 17 08 39 00 00 03 77 aa 2a 39 00 00 03 76 aa aa 23 00 00 02 84 00 39 00 00 03 78 2b ba 23 00 00 02 89 73 23 00 00 02 88 3a 23 00 00 02 85 b0 39 00 00 03 76 eb aa 23 00 00 02 94 80 39 00 00 04 87 04 07 30 23 00 00 02 93 27 23 00 00 02 af 02];
			sleep-out = [13 78 00 01 11 13 0a 00 01 29];
			linux,phandle = <0xbb>;
			phandle = <0xbb>;

			display-timings {
				clock-frequency = <0x7a120>;
				hactive = <0x1e0>;
				vactive = <0x3c0>;
				hback-porch = <0x50>;
				hfront-porch = <0x50>;
				vback-porch = <0x10>;
				vfront-porch = <0x12>;
				hsync-len = <0x14>;
				vsync-len = <0x2>;
			};
		};
	};

	sprd-headset {
		compatible = "sprd,sc2721-headset", "sprd,sc2731-headset";
		status = "okay";
		jack-type = <0x0>;
		io-channels = <0xa5 0x14>;
		io-channel-names = "headmic_in_little";
		gpios = <0x31 0x3 0x0 0x31 0x7 0x0 0x31 0xb 0x0 0x31 0x5 0x0 0x31 0xc 0x0>;
		gpio-trigger-levels = <0x1 0x1 0x1 0x1 0x1>;
		gpio-dbnc-intervals = <0x1e 0x64 0x64 0x64 0x64>;
		gpio-names = "button", "detect_l", "detect_h", "detect_mic", "detect_all";
		adc-threshold-3pole-detect = <0xb86>;
		sprd,adc-gnd = <0x1c2>;
		sprd,stable-value = <0x87a>;
		sprd,coefficient = <0xdff20>;
		irq-threshold-button = <0x9>;
		linux,phandle = <0xa6>;
		phandle = <0xa6>;

		headset-button@0 {
			adc-min = <0x0>;
			adc-max = <0x1ea>;
			code = <0xe2>;
		};

		headset-button@1 {
			adc-min = <0x21c>;
			adc-max = <0x3fc>;
			code = <0x73>;
		};

		headset-button@2 {
			adc-min = <0x442>;
			adc-max = <0x960>;
			code = <0x72>;
		};
	};

	sound@0 {
		compatible = "sprd,vbc-r1p0v3-codec-sc2721", "sprd,vbc-r1p0v3-codec-sc2731";
		status = "okay";
		sprd-audio-card,name = "sprdphone";
		sprd-audio-card,widgets = "Headphone", "inter HP PA", "Speaker", "inter Spk PA", "Speaker", "inter Ear PA";
		sprd-audio-card,routing = "HPMIC", "HP Mic Jack", "MIC", "Mic Jack", "AUXMIC", "Aux Mic Jack", "inter HP PA", "HP PA", "inter Spk PA", "Spk PA", "inter Ear PA", "EAR", "DMIC", "DMic Jack", "DMIC1", "DMic1 Jack", "Aud input", "AD Clk", "Aud input1", "AD Clk", "Aud input", "Digital ADCL Switch", "Aud input", "Digital ADCR Switch", "Aud input1", "Digital ADC1L Switch", "Aud input1", "Digital ADC1R Switch";
		sprd-audio-card,headset = <0xa6>;
		sprd-audio-card,fm-open-src = <0x1>;
		sprd-audio-card,fm-hw-rate = <0x7d00>;
		sprd-audio-card,codec-replace-adc-rate = <0xbb80>;

		sprd-audio-card,dai-link@0 {

			plat {
				sound-dai = <0xa7>;
			};

			cpu {
				sound-dai = <0xa8 0x0>;
			};

			codec {
				sound-dai = <0xa9 0x0>;
			};
		};

		sprd-audio-card,dai-link@1 {

			plat {
				sound-dai = <0xa7>;
			};

			cpu {
				sound-dai = <0xaa 0x0>;
			};

			codec {
				sound-dai = <0xa9 0x1>;
			};
		};

		sprd-audio-card,dai-link@2 {

			plat {
				sound-dai = <0xa7>;
			};

			cpu {
				sound-dai = <0xa8 0x1>;
			};

			codec {
				sound-dai = <0xa9 0x3>;
			};
		};

		sprd-audio-card,dai-link@3 {

			plat {
				sound-dai = <0xa7>;
			};

			cpu {
				sound-dai = <0xaa 0x1>;
			};

			codec {
				sound-dai = <0xa9 0x4>;
			};
		};

		sprd-audio-card,dai-link@4 {
			ops = <0x0>;

			plat {
				sound-dai = <0xa7>;
			};

			cpu {
				sound-dai = <0xa8 0x2>;
			};

			codec {
				sound-dai = <0xa9 0x5>;
			};
		};

		sprd-audio-card,dai-link@5 {

			plat {
				sound-dai = <0xa7>;
			};

			cpu {
				sound-dai = <0xa8 0x3>;
			};

			codec {
				sound-dai = <0xa9 0x6>;
			};
		};
	};

	sound@1 {
		compatible = "sprd,i2s-null-codec";
		status = "okay";
		sprd-audio-card,name = "all-i2s";

		sprd-audio-card,dai-link@0 {

			plat {
				sound-dai = <0xab>;
			};

			cpu {
				sound-dai = <0xac>;
			};

			codec {
				sound-dai = <0x0 0x0>;
			};
		};
	};

	cpwcn_btwf {
		compatible = "sprd,integrate_marlin";
		sprd,name = "wcn_btwf";
		sprd,syscon-ap-apb = <0x16>;
		sprd,syscon-ap-pmu = <0x4d>;
		sprd,syscon-anlg-wrap-wcn = <0xad>;
		sprd,ctrl-probe-num = <0x2>;
		sprd,ctrl-reg = <0xd8 0xcc 0x2050 0x20b0 0x1338>;
		sprd,ctrl-mask = <0x3 0xffff 0x3000000 0x80 0x1>;
		sprd,ctrl-value = <0x0 0x8800 0x3000000 0x80 0x1>;
		sprd,ctrl-rw-offset = <0x0 0x0 0x2000 0x2000 0x1000>;
		sprd,ctrl-us-delay = <0xa 0xa 0xa 0x3e8 0xa>;
		sprd,ctrl-type = <0x0 0x0 0x1 0x1 0x1>;
		sprd,ctrl-shutdown-reg = <0x2338>;
		sprd,ctrl-shutdown-mask = <0x1>;
		sprd,ctrl-shutdown-value = <0x1>;
		sprd,ctrl-shutdown-rw-offset = <0x2000>;
		sprd,ctrl-shutdown-us-delay = <0xa>;
		sprd,ctrl-shutdown-type = <0x1>;
		reg = <0x88000000 0x180000>;
		sprd,file-length = <0x178000>;
		memory_region = <0xae>;
		vddwcn-supply = <0xaf>;
		vddwifipa-supply = <0xb0>;
		#address-cells = <0x1>;
		#size-cells = <0x1>;
	};

	cpwcn_gnss {
		compatible = "sprd,integrate_gnss";
		sprd,name = "wcn_gnss";
		sprd,syscon-ap-apb = <0x16>;
		sprd,syscon-ap-pmu = <0x4d>;
		sprd,syscon-anlg-wrap-wcn = <0xad>;
		sprd,ctrl-probe-num = <0x2>;
		sprd,ctrl-reg = <0xd8 0xcc 0x2050 0x20b0 0x1338>;
		sprd,ctrl-mask = <0x30000003 0xffff 0x3000000 0x80 0x2>;
		sprd,ctrl-value = <0x30000000 0x8800 0x3000000 0x80 0x2>;
		sprd,ctrl-rw-offset = <0x0 0x0 0x2000 0x2000 0x1000>;
		sprd,ctrl-us-delay = <0xa 0xa 0xa 0x3e8 0xa>;
		sprd,ctrl-type = <0x0 0x0 0x1 0x1 0x1>;
		sprd,ctrl-shutdown-reg = <0x2338>;
		sprd,ctrl-shutdown-mask = <0x2>;
		sprd,ctrl-shutdown-value = <0x2>;
		sprd,ctrl-shutdown-rw-offset = <0x2000>;
		sprd,ctrl-shutdown-us-delay = <0xa>;
		sprd,ctrl-shutdown-type = <0x1>;
		reg = <0x88300000 0x100000>;
		sprd,file-length = <0x100000>;
		memory_region = <0xb1>;
		vddwcn-supply = <0xaf>;
		#address-cells = <0x1>;
		#size-cells = <0x1>;
	};

	sipc@88180000 {
		compatible = "sprd,sipc-v1";
		sprd,name = "sipc-wcn";
		sprd,dst = <0x3 0x4>;
		sprd,smem-info = <0x88180000 0x180000 0x100000>;
	};

	spipe_cpwcn {
		compatible = "sprd,spipe";
		sprd,name = "spipe_wcn";
		sprd,dst = <0x3>;
		sprd,channel = <0x4>;
		sprd,ringnr = <0x10>;
		sprd,size-rxbuf = <0x2400>;
		sprd,size-txbuf = <0x2400>;
	};

	wcn_wifi_cmd {
		compatible = "sprd,swcnblk";
		sprd,name = "wcn_wifi_cmd";
		sprd,dst = <0x3>;
		sprd,channel = <0x7>;
		sprd,tx-blksize = <0x800>;
		sprd,tx-blknum = <0x4>;
		sprd,rx-blksize = <0x800>;
		sprd,rx-blknum = <0x10>;
	};

	wcn_wifi_data0 {
		compatible = "sprd,swcnblk";
		sprd,name = "wcn_wifi_data0";
		sprd,dst = <0x3>;
		sprd,channel = <0x8>;
		sprd,tx-blksize = <0x680>;
		sprd,tx-blknum = <0x40>;
		sprd,rx-blksize = <0x680>;
		sprd,rx-blknum = <0x80>;
	};

	wcn_wifi_data1 {
		compatible = "sprd,swcnblk";
		sprd,name = "wcn_wifi_data1";
		sprd,dst = <0x3>;
		sprd,channel = <0x9>;
		sprd,tx-blksize = <0x680>;
		sprd,tx-blknum = <0x40>;
		sprd,rx-blksize = <0x0>;
		sprd,rx-blknum = <0x0>;
	};

	wcn_bt {
		compatible = "sprd,wcn_internal_chip";
		sprd,name = "ttyBT";
		sprd,dst = <0x3>;
		sprd,channel = <0x4>;
		sprd,tx_bufid = <0xb>;
		sprd,rx_bufid = <0xa>;
	};

	wcn_fm {
		compatible = "sprd,wcn_internal_chip";
		sprd,name = "fm";
		sprd,dst = <0x3>;
		sprd,tx_channel = <0x4>;
		sprd,rx_channel = <0x4>;
		sprd,tx_bufid = <0xe>;
		sprd,rx_bufid = <0xd>;
	};

	gnss_common_ctl {
		compatible = "sprd,gnss_common_ctl";
		sprd,name = "gnss_common_ctl";
	};

	sipc@8841b000 {
		compatible = "sprd,sipc-v1";
		sprd,name = "sipc-gnss";
		sprd,dst = <0x4 0x5>;
		sprd,smem-info = <0x8841b000 0x11b000 0x32000>;
	};

	spipe_gnss {
		compatible = "sprd,spipe";
		sprd,name = "sttygnss0";
		sprd,dst = <0x4>;
		sprd,channel = <0x4>;
		sprd,ringnr = <0x1>;
		sprd,size-rxbuf = <0x19000>;
		sprd,size-txbuf = <0xc800>;
	};

	battery {
		compatible = "sprd,sprd-battery";
		status = "okay";
		battery-adapt-support = <0x0>;
		battery-adapt-fun = <0x0>;
		chg-end-vol = <0x10fe>;
		chg-end-vol-check = <0x10ea>;
		chg-bat-safety-vol = <0x114e>;
		fchg-vol = <0x2328>;
		rechg-vol = <0x10ae>;
		adp-cdp-cur = <0x28a>;
		adp-dcp-cur = <0x28a>;
		adp-sdp-cur = <0x1c2>;
		adp-unknown-cur = <0x1f4>;
		adp-fchg-cur = <0xbb8>;
		adp-cdp-cur-limit = <0x5dc>;
		adp-dcp-cur-limit = <0xbb8>;
		adp-sdp-cur-limit = <0x1f4>;
		adp-fchg-cur-limit = <0x7d0>;
		adp-unknown-cur-limit = <0x1f4>;
		ovp-stop = <0x1838>;
		ovp-restart = <0x16a8>;
		fchg-ovp-stop = <0x2af8>;
		fchg-ovp-restart = <0x2710>;
		chg-timeout = <0x5460>;
		chg-rechg-timeout = <0x1518>;
		chg-end-cur = <0xb4>;
		chg-polling-time = <0xf>;
		chg-polling-time-fast = <0x1>;
		cap-one-per-time = <0x1e>;
		chg-full-condition = <0x0>;
		temp-support = <0x1>;
		temp-comp-res = <0x1e>;
		temp-tab-val = <0x46a 0x3fb 0x38a 0x31d 0x2b6 0x258 0x204 0x1b9 0x1a3 0x140 0x111 0xe8 0xc6 0xa9 0x90 0x7b 0x69 0x5a 0x4d>;
		temp-tab-temp = <0x2ee 0x320 0x352 0x384 0x3b6 0x3e8 0x41a 0x44c 0x47e 0x4b0 0x4e2 0x514 0x546 0x578 0x5aa 0x5dc 0x60e 0x640 0x672>;
		jeita-temp-tab = <0x384 0x3e8 0x44c 0x5aa 0x640>;
		jeita-temp-recovery-tab = <0x3a2 0x406 0x46a 0x58c 0x636>;
		jeita-cur-tab = <0x0 0x0 0x258 0x7fff 0x258 0x0>;
		jeita-cccv-tab = <0x1004 0x10fe 0x10fe 0x10fe 0x1004 0x1004>;
		fgu-mode = <0x0>;
		alm-soc = <0x5>;
		alm-vol = <0xd7a>;
		soft-vbat-uvlo = <0xbea>;
		rint = <0xbe>;
		cnom = <0x7b2>;
		rsense-real = <0xc8>;
		rsense-spec = <0xc8>;
		relax-current = <0x32>;
		fgu-cal-ajust = <0x0>;
		ocv-tab-vol = <0x10e4 0x1091 0x1053 0x101b 0xfe7 0xfb2 0xf87 0xf60 0xf3c 0xf10 0xeec 0xed4 0xec4 0xebc 0xeb9 0xeb4 0xea1 0xe79 0xe2c 0xddc 0xd48>;
		ocv-tab-cap = <0x64 0x5f 0x5a 0x55 0x50 0x4b 0x46 0x41 0x3c 0x37 0x32 0x2d 0x28 0x23 0x1e 0x19 0x14 0xf 0xa 0x5 0x0>;
		cnom-temp-tab = <0x3fc 0x708 0x3f2 0x514 0x3e8 0x42e 0x3de 0x3e8>;
		rint-temp-tab = <0x3fc 0xc8 0x3f2 0x1c2 0x3e8 0x28a 0x3de 0x44c>;
		charger-det-gpios = <0x31 0x0 0x0>;
		battery-det-gpios = <0x31 0x8 0x0>;
		io-channels = <0xa5 0x0 0xa5 0x5 0xa5 0xe>;
		io-channel-names = "adc_temp", "adc_vbat", "adc_vchg";
	};

	firmware {

		android {
			compatible = "android,firmware";

			vbmeta {
				compatible = "android,vbmeta";
				parts = "vbmeta,boot,recovery,system,vendor";
			};

			fstab {
				compatible = "android,fstab";

				system {
					compatible = "android,system";
					dev = "/dev/block/platform/soc/soc:ap-ahb/20600000.sdio/by-name/system";
					type = "ext4";
					mnt_flags = "ro,barrier=1";
					fsmgr_flags = "wait";
				};

				vendor {
					compatible = "android,vendor";
					dev = "/dev/block/platform/soc/soc:ap-ahb/20600000.sdio/by-name/vendor";
					type = "ext4";
					mnt_flags = "ro,barrier=1";
					fsmgr_flags = "wait";
				};
			};
		};
	};

	thermal-zones {

		cpu-thmzone {
			polling-delay-passive = <0x64>;
			polling-delay = <0x3e8>;
			sustainable-power = <0x3e8>;
			thermal-sensors = <0xb2 0x0>;

			trips {

				trip-point@0 {
					temperature = <0x11170>;
					hysteresis = <0x3e8>;
					type = "passive";
				};

				trip-point@1 {
					temperature = <0x14c08>;
					hysteresis = <0x3e8>;
					type = "passive";
					linux,phandle = <0xb3>;
					phandle = <0xb3>;
				};

				cpu_crit {
					temperature = <0x1adb0>;
					hysteresis = <0x7d0>;
					type = "critical";
				};
			};

			cooling-maps {

				map0 {
					trip = <0xb3>;
					contribution = <0x400>;
					cooling-device = <0xb4 0xffffffff 0xffffffff>;
				};
			};
		};

		chg-thmzone {
			polling-delay-passive = <0x0>;
			polling-delay = <0x0>;
			thermal-sensors = <0xb5 0x9>;
		};

		board-thmzone {
			polling-delay-passive = <0x0>;
			polling-delay = <0x0>;
			thermal-sensors = <0xb6 0xa>;
		};
	};

	cooling-devices {

		cluster0-cooling {
			compatible = "sprd,cluster-cooling";
			#cooling-cells = <0x2>;
			sprd,efuse-block7 = <0x7>;
			sprd,efuse-block15 = <0xf>;
			sprd,leak-core = <0x2 0x55 0x74d>;
			sprd,leak-cluster = <0x2 0x55 0x9dc>;
			sprd,core-temp-scale = <0x1e 0xfffff572 0x22e7a 0xffec36f3>;
			sprd,core-voltage-scale = <0x2d2 0xfffffa4d 0x4a6 0xfffffec4>;
			sprd,cluster-temp-scale = <0x1e 0xfffff5cf 0x22242 0xffed98c2>;
			sprd,cluster-voltage-scale = <0x266 0xfffffbaa 0x335 0xffffff44>;
			sprd,efuse-switch = <0x0>;
			sprd,hotplug-period = <0xa>;
			sprd,min-cpufreq = <0xbb800>;
			sprd,min-cpunum = <0x4>;
			sprd,core-base = <0x473>;
			sprd,cluster-base = <0xabf>;
			sprd,dynamic-core = <0x330 0x300 0x384>;
			sprd,dynamic-cluster = <0xf 0x300 0x384>;
			linux,phandle = <0xb4>;
			phandle = <0xb4>;
		};
	};

	chg-tsensor@9 {
		compatible = "sprd,board-thermal";
		#thermal-sensor-cells = <0x1>;
		io-channels = <0xa5 0x2>;
		io-channel-names = "adc_temp";
		temp-tab-size = <0xf>;
		temp-tab-val = <0x46b 0x456 0x432 0x3d7 0x346 0x28e 0x19d 0x13c 0xee 0xb2 0x85 0x64 0x4b 0x39 0x2b>;
		temp-tab-temp = <0x25b 0x2be 0x325 0x3b9 0x44d 0x4e0 0x5a9 0x60d 0x671 0x6d5 0x739 0x79d 0x801 0x865 0x8c9>;
		status = "disabled";
		linux,phandle = <0xb5>;
		phandle = <0xb5>;
	};

	bd-tsensor@10 {
		compatible = "sprd,board-thermal";
		#thermal-sensor-cells = <0x1>;
		io-channels = <0xa5 0x1>;
		io-channel-names = "adc_temp";
		temp-tab-size = <0xf>;
		temp-tab-val = <0x46b 0x456 0x432 0x3d7 0x346 0x28e 0x19d 0x13c 0xee 0xb2 0x85 0x64 0x4b 0x39 0x2b>;
		temp-tab-temp = <0x25b 0x2be 0x325 0x3b9 0x44d 0x4e0 0x5a9 0x60d 0x671 0x6d5 0x739 0x79d 0x801 0x865 0x8c9>;
		linux,phandle = <0xb6>;
		phandle = <0xb6>;
	};

	reserved-memory {
		#address-cells = <0x1>;
		#size-cells = <0x1>;
		ranges;

		sipc-mem@87800000 {
			reg = <0x87800000 0x200000>;
			linux,phandle = <0xc3>;
			phandle = <0xc3>;
		};

		wcn-mem@88000000 {
			reg = <0x88000000 0x280000>;
			linux,phandle = <0xae>;
			phandle = <0xae>;
		};

		gnss-mem@88300000 {
			reg = <0x88300000 0x15a800>;
			linux,phandle = <0xb1>;
			phandle = <0xb1>;
		};

		cp-modem@89600000 {
			reg = <0x89600000 0x2300000>;
			linux,phandle = <0xc2>;
			phandle = <0xc2>;
		};

		iq-mem@93100000 {
			compatible = "sprd,iq-mem";
			reg = <0x93100000 0x4000000>;
			linux,phandle = <0xb8>;
			phandle = <0xb8>;
		};

		sml-mem@94000000 {
			reg = <0x94000000 0x100000>;
		};

		tos-mem@94100000 {
			reg = <0x94100000 0x200000>;
		};

		pstore@9e524000 {
			reg = <0x9e524000 0x40000>;
			linux,phandle = <0xb7>;
			phandle = <0xb7>;
		};
	};

	ramoops {
		compatible = "ramoops";
		memory-region = <0xb7>;
		record-size = <0x0 0x8000>;
		console-size = <0x0 0x8000>;
		pmsg-size = <0x0 0x8000>;
	};

	sprd-iq {
		compatible = "sprd,iq";
		sprd,region = <0xb8>;
		sprd,mapping-offs = <0x0>;
	};

	sprd-panel-if {
		compatible = "sprd-panel-if";
		#address-cells = <0x1>;
		#size-cells = <0x0>;
		panel-drivers = <0xb9 0xba 0xbb 0xbc>;

		port@1 {
			reg = <0x1>;

			endpoint@0 {
				remote-endpoint = <0xbd>;
				linux,phandle = <0x42>;
				phandle = <0x42>;
			};
		};
	};

	sprd-adf {
		compatible = "sprd,sprd-adf";
		status = "okay";
		sprd,display-mode = <0x3>;
		sprd,dispc = <0xbe>;
	};

	sprd-wlan {
		compatible = "sprd,sp7731e";
	};

	sprd_backlight {
		compatible = "pwm-backlight";
		pwms = <0xbf 0x0 0x4e20>;
		pwm-names = "backlight";
		brightness_max = <0x100>;
		brightness-levels = <0x3 0x3 0x3 0x3 0x3 0x3 0x3 0x3 0x3 0x3 0x3 0x5 0x7 0x9 0xa 0xb 0xc 0xd 0xe 0xf 0x10 0x11 0x12 0x13 0x14 0x15 0x16 0x17 0x18 0x19 0x1a 0x1b 0x1c 0x1d 0x1e 0x1f 0x20 0x21 0x22 0x23 0x24 0x25 0x26 0x27 0x28 0x29 0x2a 0x2b 0x2c 0x2d 0x2e 0x2f 0x30 0x31 0x32 0x33 0x34 0x35 0x36 0x37 0x38 0x39 0x3a 0x3b 0x3c 0x3d 0x3e 0x3f 0x40 0x41 0x42 0x43 0x44 0x45 0x46 0x47 0x48 0x49 0x4a 0x4b 0x4c 0x4d 0x4e 0x4f 0x50 0x51 0x52 0x53 0x54 0x55 0x56 0x57 0x58 0x59 0x5a 0x5b 0x5c 0x5d 0x5e 0x5f 0x60 0x61 0x62 0x63 0x64 0x65 0x66 0x67 0x68 0x69 0x6a 0x6b 0x6c 0x6d 0x6e 0x6f 0x70 0x71 0x72 0x73 0x74 0x75 0x76 0x77 0x78 0x79 0x7a 0x7b 0x7c 0x7d 0x7e 0x7f 0x80 0x81 0x82 0x83 0x84 0x85 0x86 0x87 0x88 0x89 0x8a 0x8b 0x8c 0x8d 0x8e 0x8f 0x90 0x91 0x92 0x93 0x94 0x95 0x96 0x97 0x98 0x99 0x9a 0x9b 0x9c 0x9d 0x9e 0x9f 0xa0 0xa1 0xa2 0xa3 0xa4 0xa5 0xa6 0xa7 0xa8 0xa9 0xaa 0xab 0xac 0xad 0xae 0xaf 0xb0 0xb1 0xb2 0xb3 0xb4 0xb5 0xb6 0xb7 0xb8 0xb9 0xba 0xbb 0xbc 0xbd 0xbe 0xbf 0xc0 0xc1 0xc2 0xc3 0xc4 0xc5 0xc6 0xc7 0xc8 0xc9 0xca 0xcb 0xcc 0xcd 0xce 0xcf 0xd0 0xd1 0xd2 0xd3 0xd4 0xd5 0xd6 0xd7 0xd8 0xd9 0xda 0xdb 0xdc 0xdd 0xde 0xdf 0xe0 0xe1 0xe2 0xe3 0xe4 0xe5 0xe6 0xe7 0xe8 0xe9 0xea 0xeb 0xec 0xed 0xee 0xef 0xf0 0xf1 0xf2 0xf3 0xf4 0xf5 0xf6 0xf7 0xf8 0xf9 0xfa 0xfb>;
		default-brightness-level = <0x66>;
	};

	scene-frequency {
		compatible = "sprd,dfs";
		sprd-scene = "lcdon", "lcdoff", "camlow", "camhigh";
		sprd-freq = <0x100 0x100 0x180 0x215>;
		overflow = <0x5db060 0x8ca000 0xffffffff 0xffffffff>;
		underflow = <0x1 0x5c29c0 0x7d5dc0 0xffffffff>;
	};

	sprd-hotplug {
		enable-dynamic-hotplug;
	};

	memory@80000000 {
		device_type = "memory";
		reg = <0x80000000 0x20000000>;
		linux,phandle = <0xc1>;
		phandle = <0xc1>;
	};

	chosen {
		bootargs = "earlycon=sprd_serial,0x70100000,115200n8 loglevel=1 console=ttyS1,115200n8 init=/init root=/dev/ram0 rw androidboot.hardware=y400";
		linux,initrd-start = <0x85500000>;
		linux,initrd-end = <0x855a3212>;
	};

	ion {
		compatible = "sprd,ion";
		#address-cells = <0x1>;
		#size-cells = <0x0>;

		heap@0 {
			reg = <0x0>;
			label = "system";
			type = <0x0>;
		};
	};

	interrupt-controller {
		compatible = "android,CustomIPI";
		#interrupt-cells = <0x1>;
		interrupt-controller;
		linux,phandle = <0xc0>;
		phandle = <0xc0>;
	};

	trusty {
		compatible = "android,trusty-smc-v1";

		irq {
			compatible = "android,trusty-irq-v1";
			interrupt-templates = <0xc0 0x0 0x1 0x1 0x1 0x0 0x1 0x1 0x0 0x0>;
			interrupt-ranges = <0x0 0xf 0x0 0x10 0x1f 0x1 0x20 0xdf 0x2>;
		};

		virtio {
			compatible = "android,trusty-virtio-v1";
		};

		log {
			compatible = "android,trusty-log-v1";
		};
	};

	sprd-cm4-memory {
		#address-cells = <0x1>;
		#size-cells = <0x1>;
		ranges;

		cm4_iram@50800000 {
			reg = <0x50800000 0x10000>;
			linux,phandle = <0xc4>;
			phandle = <0xc4>;
		};
	};

	sprd-sysdump {
		memory-region = <0xc1>;
		memory-region-re = <0xc2 0xc3 0xb1 0xae 0xc4>;
	};

	sprd_scale {
		compatible = "sprd,sprd_scale";
		iommus = <0x62>;
		status = "okay";
	};

	sprd_rotation {
		compatible = "sprd,sprd_rotation";
		sprd,cam-ahb-syscon = <0x60>;
		iommus = <0x62>;
		status = "okay";
	};

	gpio-keys {
		compatible = "gpio-keys";
		input-name = "sprd-gpio-keys";
		status = "okay";

		key-volumedown {
			label = "Volume Down Key";
			linux,code = <0x72>;
			gpios = <0xc5 0x3 0x1>;
			debounce-interval = <0x2>;
			gpio-key,wakeup;
			gpio-key,level-trigger;
		};

		key-volumeup {
			label = "Volume Up Key";
			linux,code = <0x73>;
			gpios = <0xc5 0x2 0x1>;
			debounce-interval = <0x2>;
			gpio-key,wakeup;
			gpio-key,level-trigger;
		};

		key-power {
			label = "Power Key";
			linux,code = <0x74>;
			gpios = <0x31 0x1 0x1>;
			debounce-interval = <0x2>;
			gpio-key,wakeup;
			gpio-key,level-trigger;
		};
	};

	hall-detect {
		compatible = "hall-detect";
		linux,code = <0xf9>;
		gpios = <0x25 0x2 0x0>;
		debounce-interval = <0x14>;
		gpio-key,wakeup;
	};

	flash-gpios {
		compatible = "sprd,flash-wd3124da";
		flash-ic = <0xc34>;
		flash-torch-en-gpios = <0x25 0xc 0x0>;
		flash-en-gpios = <0x25 0xd 0x0>;
	};
};
